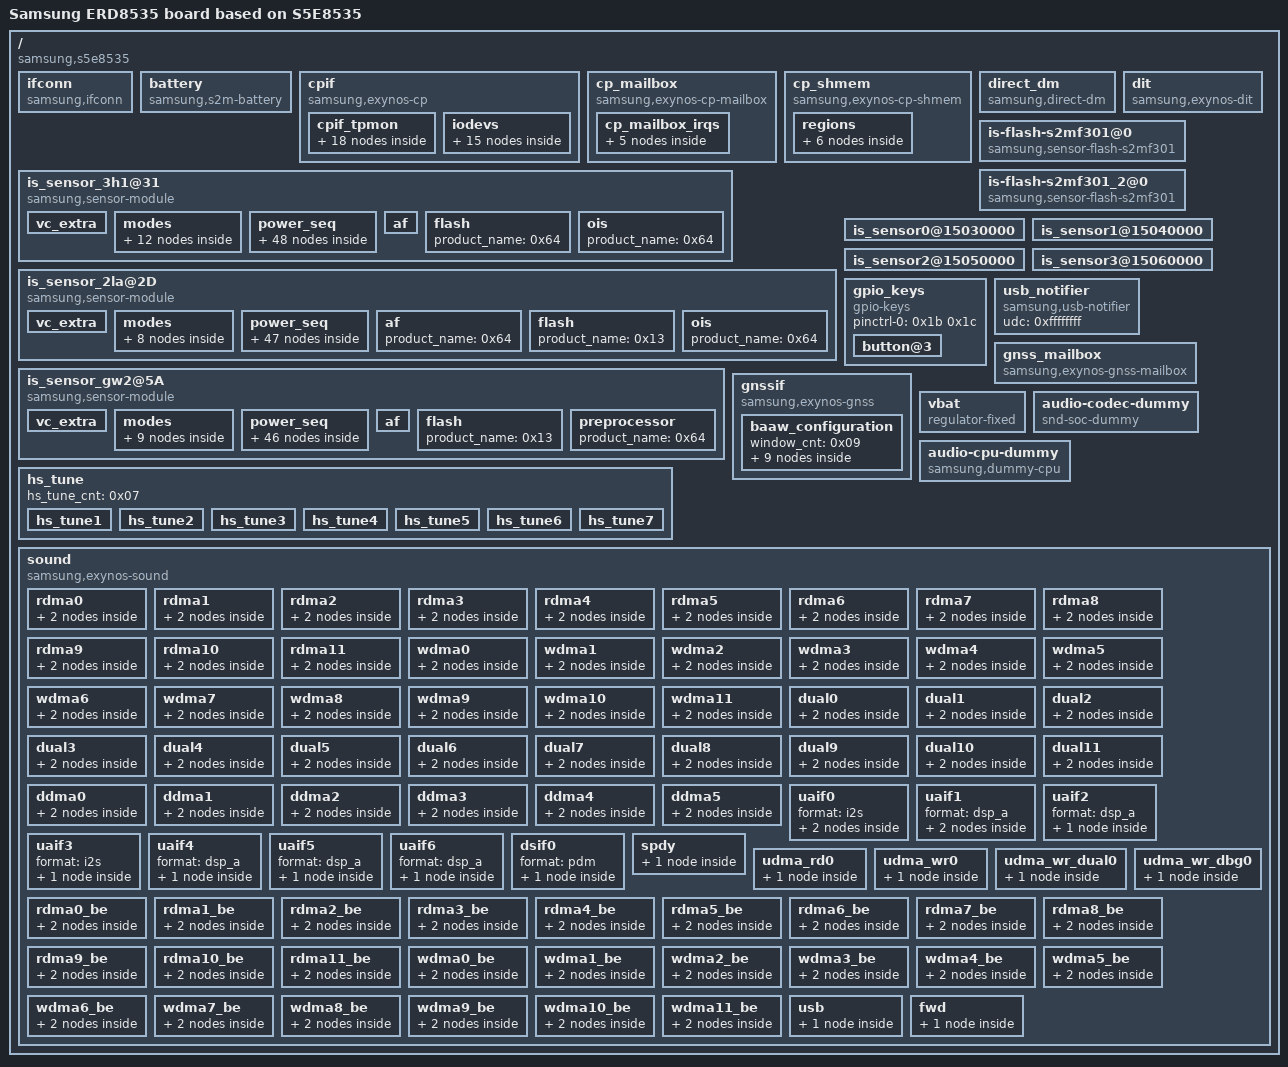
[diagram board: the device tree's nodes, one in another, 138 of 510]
/dts-v1/;

/ {
	compatible = "samsung,s5e8535\0samsung,ERD8535";
	board_id = <0x00>;
	board_rev = <0x00>;

	fragment@battery {
		target-path = "/";

		__overlay__ {

			ifconn {
				status = "okay";
				compatible = "samsung,ifconn";
				ifconn,usbpd = "s2mf301";
				ifconn,muic = "s2mf301-muic";
			};

			battery {
				status = "okay";
				compatible = "samsung,s2m-battery";
				pinctrl-names = "default";
				battery,vendor = "SDI SDI";
				battery,charger_name = "dc-manager";
				battery,direct_charger_name = "s2mc501-direct-charger";
				battery,switching_charger_name = "s2mf301-charger";
				battery,fuelgauge_name = "s2mf301-fuelgauge";
				battery,pmeter_name = "s2mf301-pmeter";
				battery,technology = <0x02>;
				battery,temp_high = <0x1f4>;
				battery,temp_high_recovery = <0x1c2>;
				battery,temp_low = <0x64>;
				battery,temp_low_recovery = <0x96>;
				battery,low_temp_limit = <0x64>;
				battery,chg_float_voltage = <0x10fe>;
				battery,full_check_count = <0x03>;
				battery,chg_full_vcell = <0x1108>;
				battery,chg_recharge_vcell = <0x10cc>;
				battery,max_rawsoc = <0x3e8>;
				battery,max_rawsoc_offset = <0x0a>;
				battery,default_input_current = <0x3e8>;
				battery,default_charging_current = <0x3e8>;
				battery,default_full_check_current = <0x12c>;
				battery,max_input_current = <0xbb8>;
				battery,max_charging_current = <0xbb8>;
				battery,pdo_max_input_vol = <0x32c8>;
				battery,pdo_max_chg_power = <0x61a8>;
				battery,input_current_limit = <0x1f4 0x1c2 0x1f4 0x7d0 0x1f4 0x4b0 0x4b0 0x3e8 0x3e8 0x5dc 0x3e8 0x1f4 0x1f4>;
				battery,fast_charging_current = <0x1f4 0x1c2 0x1f4 0x7d0 0x1f4 0x4b0 0x4b0 0x3e8 0x3e8 0xbb8 0x3e8 0x1f4 0x1f4>;
				battery,full_check_current = <0x12c 0x00 0x12c 0x12c 0x12c 0x12c 0x12c 0x12c 0x12c 0x12c 0x12c 0x12c 0x12c>;
				battery,input_current_limit_expand = <0xbb8 0x5dc 0x1f4 0x1c2>;
				battery,fast_charging_current_expand = <0xbb8 0xbb8 0x1f4 0x1c2>;
				battery,full_check_current_expand = <0x12c 0x12c 0x12c 0x00>;
				battery,thermal_limit_level = <0x258 0x2bc 0x320 0x384 0x3e8 0x44c 0x4b0>;
				battery,battery_table3 = <0x58 0x0b 0xd6 0x0a 0x54 0x0a 0xda 0x09 0x64 0x09 0xf3 0x08 0x8c 0x08 0x22 0x08 0xcd 0x07 0x7b 0x07 0x08 0x07 0xc6 0x06 0x97 0x06 0x71 0x06 0x54 0x06 0x39 0x06 0x0f 0x06 0xea 0x05 0xaf 0x05 0x85 0x05 0xfd 0x04 0xb2 0x01 0x69 0x08 0x00 0x08 0x97 0x07 0x2d 0x07 0xc4 0x06 0x5a 0x06 0xf1 0x05 0x87 0x05 0x1e 0x05 0xb5 0x04 0x4b 0x04 0xe2 0x03 0x78 0x03 0x0f 0x03 0xa6 0x02 0x3c 0x02 0xd3 0x01 0x69 0x01 0x00 0x01 0x96 0x00 0x2d 0x00 0xda 0x0f>;
				battery,battery_table4 = <0x21 0x21 0x21 0x21 0x21 0x21 0x21 0x21 0x21 0x20 0x20 0x21 0x21 0x21 0x21 0x22 0x22 0x22 0x22 0x24 0x26 0x7c>;
				battery,batcap = <0x8c 0x44 0x23 0x11>;
				battery,accum = <0x08 0x00>;
				battery,soc_arr_val = <0x2912 0x2710 0x250d 0x230a 0x2107 0x1f05 0x1d02 0x1aff 0x18fc 0x16fa 0x14f7 0x12f4 0x10f2 0xeef 0xcec 0xae9 0x8e7 0x6e4 0x4e1 0x2de 0xdc 0xffffff47>;
				battery,ocv_arr_val = <0xac93 0xaa18 0xa79e 0xa54b 0xa30c 0xa0e4 0x9eeb 0x9ce7 0x9b45 0x99b7 0x9787 0x9645 0x955d 0x94a6 0x9417 0x9392 0x92c6 0x920e 0x90f2 0x9024 0x8d8c 0x7d78>;
				battery,battery_param_ver = <0x03>;
			};
		};
	};

	fragment@modemif {
		target-path = "/";

		__overlay__ {
			#address-cells = <0x02>;
			#size-cells = <0x01>;

			cpif {
				compatible = "samsung,exynos-cp";
				status = "okay";
				pinctrl-names = "default";
				pinctrl-0 = <0x01>;
				interrupt-parent = <0xffffffff>;
				interrupts = <0x00 0x14f 0x04>;
				interrupt-names = "RESET_REQ";
				ap2cp_cfg_addr = <0x14020000>;
				mif,name = "s5408ap";
				mif,cp_num = <0x00>;
				mif,modem_type = <0x00>;
				mif,protocol = <0x01>;
				mif,ipc_version = <0x32>;
				mif,link_type = <0x00>;
				mif,link_name = "shmem";
				mif,link_attrs = <0x7c8>;
				mif,interrupt_types = <0x00>;
				mif,capability_check = <0x01>;
				mif,int_ap2cp_msg = <0x00>;
				mif,int_ap2cp_wakeup = <0x01>;
				mif,int_ap2cp_status = <0x02>;
				mif,int_ap2cp_active = <0x03>;
				mif,int_ap2cp_lcd_status = <0x04>;
				mif,int_ap2cp_llc_status = <0x05>;
				mif,int_ap2cp_clatinfo_send = <0x06>;
				mif,int_ap2cp_cp_reset_noti = <0x07>;
				mif,int_ap2cp_uart_noti = <0x0f>;
				mif,irq_cp2ap_msg = <0x00>;
				mif,irq_cp2ap_status = <0x02>;
				mif,irq_cp2ap_active = <0x03>;
				mif,irq_cp2ap_llc_status = <0x05>;
				mif,irq_cp2ap_clatinfo_ack = <0x06>;
				mif,irq_cp2ap_wakelock = <0x08>;
				mif,irq_cp2ap_ratmode = <0x09>;
				legacy_fmt_head_tail_offset = <0x10>;
				legacy_fmt_buffer_offset = <0x1000>;
				legacy_fmt_txq_size = <0x1000>;
				legacy_fmt_rxq_size = <0x1000>;
				legacy_raw_head_tail_offset = <0x20>;
				legacy_raw_buffer_offset = <0x3000>;
				legacy_raw_txq_size = <0x1fd000>;
				legacy_raw_rxq_size = <0x200000>;
				legacy_raw_qos_head_tail_offset = <0x30>;
				legacy_raw_qos_buffer_offset = <0x400000>;
				legacy_raw_qos_txq_size = <0x100000>;
				legacy_raw_qos_rxq_size = <0x100000>;
				legacy_raw_rx_buffer_cached = <0x00>;
				offset_cmsg_offset = <0x60>;
				offset_srinfo_offset = <0x64>;
				offset_clk_table_offset = <0x68>;
				offset_buff_desc_offset = <0x6c>;
				offset_capability_offset = <0x70>;
				cmsg_offset = <0xc0>;
				srinfo_offset = <0x300>;
				srinfo_size = <0x800>;
				clk_table_offset = <0x200>;
				buff_desc_offset = <0xc00>;
				capability_offset = <0xa0>;
				ap_capability_0 = <0x00>;
				ap_capability_1 = <0x00>;
				ap2cp_msg = <0x03 0x00>;
				cp2ap_msg = <0x03 0x04>;
				ap2cp_united_status = <0x03 0x08>;
				cp2ap_united_status = <0x03 0x0c>;
				ap2cp_llc_status = <0x03 0x10>;
				cp2ap_llc_status = <0x03 0x14>;
				ap2cp_clatinfo_xlat_v4_addr = <0x03 0x18>;
				ap2cp_clatinfo_xlat_addr_0 = <0x03 0x1c>;
				ap2cp_clatinfo_xlat_addr_1 = <0x03 0x20>;
				ap2cp_clatinfo_xlat_addr_2 = <0x03 0x24>;
				ap2cp_clatinfo_xlat_addr_3 = <0x03 0x28>;
				ap2cp_clatinfo_index = <0x03 0x2c>;
				ap2cp_kerneltime_sec = <0x03 0x38>;
				ap2cp_kerneltime_usec = <0x03 0x3c>;
				sbi_lcd_status_mask = <0x01>;
				sbi_lcd_status_pos = <0x1b>;
				sbi_crash_type_mask = <0x0f>;
				sbi_crash_type_pos = <0x17>;
				sbi_ext_backtrace_mask = <0x01>;
				sbi_ext_backtrace_pos = <0x11>;
				sbi_ext_backtrace_ext_mask = <0x01>;
				sbi_ext_backtrace_ext_pos = <0x12>;
				sbi_uart_noti_mask = <0x01>;
				sbi_uart_noti_pos = <0x10>;
				sbi_ds_det_mask = <0x03>;
				sbi_ds_det_pos = <0x0e>;
				sbi_sys_rev_mask = <0xff>;
				sbi_sys_rev_pos = <0x06>;
				sbi_pda_active_mask = <0x01>;
				sbi_pda_active_pos = <0x05>;
				sbi_tx_flowctl_mask = <0x01>;
				sbi_tx_flowctl_pos = <0x03>;
				sbi_ap_status_mask = <0x01>;
				sbi_ap_status_pos = <0x01>;
				sbi_cp_rat_mode_mask = <0x3f>;
				sbi_cp_rat_mode_pos = <0x1a>;
				sbi_cp_evs_mode_mask = <0x01>;
				sbi_cp_evs_mode_pos = <0x07>;
				sbi_cp2ap_wakelock_mask = <0x01>;
				sbi_cp2ap_wakelock_pos = <0x06>;
				sbi_lte_active_mask = <0x01>;
				sbi_lte_active_pos = <0x05>;
				sbi_cp_status_mask = <0x0f>;
				sbi_cp_status_pos = <0x01>;
				sbi_ap_llc_request_mask = <0x01>;
				sbi_ap_llc_request_pos = <0x0e>;
				sbi_ap_llc_target_mask = <0x01>;
				sbi_ap_llc_target_pos = <0x0d>;
				sbi_ap_llc_return_mask = <0x0f>;
				sbi_ap_llc_return_pos = <0x09>;
				sbi_ap_llc_alloc_mask = <0x01>;
				sbi_ap_llc_alloc_pos = <0x08>;
				sbi_ap_llc_way_mask = <0xff>;
				sbi_ap_llc_way_pos = <0x00>;
				sbi_cp_llc_request_mask = <0x01>;
				sbi_cp_llc_request_pos = <0x0e>;
				sbi_cp_llc_target_mask = <0x01>;
				sbi_cp_llc_target_pos = <0x0d>;
				sbi_cp_llc_return_mask = <0x0f>;
				sbi_cp_llc_return_pos = <0x09>;
				sbi_cp_llc_alloc_mask = <0x01>;
				sbi_cp_llc_alloc_pos = <0x08>;
				sbi_cp_llc_way_mask = <0xff>;
				sbi_cp_llc_way_pos = <0x00>;
				cp_btl_node_name = "ramdump_memshare";
				s2d_req_handle_support = <0x01>;
				s2d_req_pmu_reg = <0x3540>;
				s2d_req_reg_mask = <0x07>;
				pktproc_use_36bit_addr = <0x00>;
				pktproc_cp_base = <0x00 0x50800000>;
				pktproc_dl_support = <0x01>;
				pktproc_dl_version = <0x02>;
				pktproc_dl_info_rgn_offset = <0x00>;
				pktproc_dl_info_rgn_size = <0x1000>;
				pktproc_dl_desc_rgn_offset = <0x2000>;
				pktproc_dl_desc_rgn_size = <0xfe000>;
				pktproc_dl_buff_rgn_offset = <0x200000>;
				pktproc_dl_buff_rgn_size = <0x1200000>;
				pktproc_dl_info_rgn_cached = <0x00>;
				pktproc_dl_desc_rgn_cached = <0x00>;
				pktproc_dl_buff_rgn_cached = <0x00>;
				pktproc_dl_desc_mode = <0x01>;
				pktproc_dl_num_queue = <0x01>;
				pktproc_dl_use_exclusive_irq = <0x01>;
				pktproc_dl_exclusive_irq_idx = <0x01 0x02 0x03 0x04>;
				pktproc_dl_use_netrx_mng = <0x00>;
				pktproc_dl_use_hw_iocc = <0x00>;
				pktproc_dl_max_packet_size = <0x800>;
				pktproc_dl_use_dedicated_baaw = <0x00>;
				pktproc_ul_support = <0x01>;
				pktproc_ul_info_rgn_offset = <0x1000>;
				pktproc_ul_info_rgn_size = <0x1000>;
				pktproc_ul_desc_rgn_offset = <0x100000>;
				pktproc_ul_desc_rgn_size = <0x100000>;
				pktproc_ul_buff_rgn_offset = <0x1400000>;
				pktproc_ul_buff_rgn_size = <0x400000>;
				pktproc_ul_padding_required = <0x01>;
				pktproc_ul_num_queue = <0x02>;
				pktproc_ul_max_packet_size = <0x800>;
				pktproc_ul_info_rgn_cached = <0x00>;
				pktproc_ul_desc_rgn_cached = <0x00>;
				pktproc_ul_buff_rgn_cached = <0x00>;
				pktproc_ul_use_hw_iocc = <0x00>;
				devfreq_use_dfs_max_freq = <0x01>;
				devfreq_cal_id_mif = <0xb040000>;

				cpif_tpmon {
					trigger_msec_min = <0x1f4>;
					trigger_msec_max = <0x5dc>;
					monitor_interval_msec = <0x3e8>;
					monitor_hold_msec = <0xbb8>;
					monitor_stop_mbps = <0x0f>;
					boost_hold_msec = <0x1770>;

					tpmon_rps {
						boost_name = "RPS";
						target = <0x00>;
						extra_idx = <0x00>;
						level = <0x13 0x80>;

						boost0 {
							enable = <0x01>;
							measure = <0x00>;
							proto = <0x00>;
							boost_threshold = <0x12c>;
							unboost_threshold_mbps = <0x78>;
						};
					};

					tpmon_gro_flush_time {
						boost_name = "GRO";
						target = <0x01>;
						extra_idx = <0x00>;
						level = <0x1e8480 0x1e8480 0x1e8480>;

						boost0 {
							enable = <0x01>;
							measure = <0x00>;
							proto = <0x00>;
							boost_threshold = <0x64 0xc8>;
							unboost_threshold_mbps = <0x32 0x78>;
						};
					};

					tpmon_mif {
						boost_name = "MIF";
						target = <0x02>;
						extra_idx = <0x00>;
						level = <0x00 0xf78f0>;

						boost0 {
							enable = <0x01>;
							measure = <0x00>;
							proto = <0x01>;
							boost_threshold = <0x2bc>;
							unboost_threshold_mbps = <0x12c>;
						};
					};

					tpmon_cpu_cl0 {
						boost_name = "CL0";
						target = <0x09>;
						extra_idx = <0x00>;
						level = <0x00 0x101d00 0x119400>;

						boost0 {
							enable = <0x00>;
							measure = <0x00>;
							proto = <0x01>;
							boost_threshold = <0x64 0x12c>;
							unboost_threshold_mbps = <0x28 0x78>;
						};
					};

					tpmon_cpu_cl1 {
						boost_name = "CL1";
						target = <0x0a>;
						extra_idx = <0x06>;
						level = <0x00 0xbb800 0x119400 0x177000>;

						boost0 {
							enable = <0x00>;
							measure = <0x00>;
							proto = <0x01>;
							boost_threshold = <0x1f4 0x2bc 0x5dc>;
							unboost_threshold_mbps = <0xc8 0x12c 0x258>;
						};
					};

					tpmon_irq_dit {
						boost_name = "IRQ_DIT";
						target = <0x06>;
						extra_idx = <0x00>;
						level = <0x20 0x40>;

						boost0 {
							enable = <0x01>;
							measure = <0x00>;
							proto = <0x00>;
							boost_threshold = <0x7d0>;
							unboost_threshold_mbps = <0x320>;
						};

						boost1 {
							enable = <0x01>;
							measure = <0x02>;
							proto = <0x00>;
							boost_threshold = <0x1770>;
							unboost_threshold_mbps = <0x7d0>;
						};

						boost2 {
							enable = <0x01>;
							measure = <0x03>;
							proto = <0x00>;
							boost_threshold = <0x1b58>;
							unboost_threshold_mbps = <0x7d0>;
						};
					};

					tpmon_int_freq {
						boost_name = "INT";
						target = <0x07>;
						extra_idx = <0x00>;
						level = <0x00 0x61a80 0x82208>;

						boost0 {
							enable = <0x01>;
							measure = <0x00>;
							proto = <0x00>;
							boost_threshold = <0x6d6 0xbb8>;
							unboost_threshold_mbps = <0x320 0x4b0>;
						};
					};

					tpmon_bts_dit {
						boost_name = "BTS_DIT";
						target = <0x08>;
						extra_idx = <0x00>;
						level = <0x00 0x01>;

						boost0 {
							enable = <0x01>;
							measure = <0x03>;
							proto = <0x00>;
							boost_threshold = <0xfa0>;
							unboost_threshold_mbps = <0x12c>;
						};
					};
				};

				iodevs {

					io_device_0 {
						iod,name = "umts_ipc";
						iod,ch = <0xf5>;
						iod,format = <0x00>;
						iod,io_type = <0x01>;
						iod,link_type = <0x00>;
						iod,attrs = <0x2000>;
						iod,ch_count = <0x02>;
					};

					io_device_1 {
						iod,name = "umts_rfs0";
						iod,ch = <0x29>;
						iod,format = <0x01>;
						iod,io_type = <0x01>;
						iod,link_type = <0x00>;
						iod,attrs = <0x00>;
					};

					io_device_2 {
						iod,name = "umts_router";
						iod,ch = <0x15>;
						iod,format = <0x01>;
						iod,io_type = <0x01>;
						iod,link_type = <0x00>;
						iod,attrs = <0x00>;
					};

					io_device_3 {
						iod,name = "umts_dm0";
						iod,ch = <0x51>;
						iod,format = <0x01>;
						iod,io_type = <0x01>;
						iod,link_type = <0x00>;
						iod,attrs = <0x4000>;
					};

					io_device_4 {
						iod,name = "umts_loopback";
						iod,ch = <0x52>;
						iod,format = <0x01>;
						iod,io_type = <0x01>;
						iod,link_type = <0x00>;
						iod,attrs = <0x00>;
					};

					io_device_5 {
						iod,name = "rmnet";
						iod,ch = <0xb5>;
						iod,format = <0x01>;
						iod,io_type = <0x02>;
						iod,link_type = <0x00>;
						iod,attrs = <0x2000>;
						iod,ch_count = <0x1e>;
					};

					io_device_6 {
						iod,name = "umts_dummy";
						iod,ch = <0xd3>;
						iod,format = <0x01>;
						iod,io_type = <0x02>;
						iod,link_type = <0x00>;
						iod,attrs = <0x00>;
					};

					io_device_7 {
						iod,name = "multipdp";
						iod,ch = <0x00>;
						iod,format = <0x03>;
						iod,io_type = <0x03>;
						iod,link_type = <0x00>;
						iod,attrs = <0x00>;
					};

					io_device_8 {
						iod,name = "umts_boot0";
						iod,ch = <0xf1>;
						iod,format = <0x04>;
						iod,io_type = <0x00>;
						iod,link_type = <0x00>;
						iod,attrs = <0x4200>;
					};

					io_device_9 {
						iod,name = "umts_rcs0";
						iod,ch = <0x5b>;
						iod,format = <0x00>;
						iod,io_type = <0x01>;
						iod,link_type = <0x00>;
						iod,attrs = <0x00>;
					};

					io_device_10 {
						iod,name = "umts_rcs1";
						iod,ch = <0x5c>;
						iod,format = <0x01>;
						iod,io_type = <0x01>;
						iod,link_type = <0x00>;
						iod,attrs = <0x00>;
					};

					io_device_11 {
						iod,name = "umts_wfc0";
						iod,ch = <0x5d>;
						iod,format = <0x00>;
						iod,io_type = <0x01>;
						iod,link_type = <0x00>;
						iod,attrs = <0x00>;
					};

					io_device_12 {
						iod,name = "umts_wfc1";
						iod,ch = <0x5e>;
						iod,format = <0x01>;
						iod,io_type = <0x01>;
						iod,link_type = <0x00>;
						iod,attrs = <0x00>;
					};

					io_device_13 {
						iod,name = "umts_embms";
						iod,ch = <0x1e>;
						iod,format = <0x01>;
						iod,io_type = <0x02>;
						iod,link_type = <0x00>;
						iod,attrs = <0x2000>;
						iod,ch_count = <0x02>;
					};

					io_device_14 {
						iod,name = "umts_atc0";
						iod,ch = <0x17>;
						iod,format = <0x01>;
						iod,io_type = <0x01>;
						iod,link_type = <0x00>;
						iod,attrs = <0x00>;
					};
				};
			};

			cp_mailbox {
				compatible = "samsung,exynos-cp-mailbox";
				reg = <0x00 0x119b0000 0x200>;
				num_shared_reg = <0x0a>;
				shared_reg_offset = <0x100>;
				use_sw_reset_reg = <0x00>;
				interrupt-parent = <0xffffffff>;
				interrupts = <0x00 0x27 0x04 0x00 0x28 0x04 0x00 0x29 0x04 0x00 0x2a 0x04 0x00 0x2b 0x04>;

				cp_mailbox_irqs {

					cp_irq_0 {
						cp_irq,enable = <0x01>;
						cp_irq,idx = <0x00>;
						cp_irq,name = "cp_mbox_irq_0";
						cp_irq,sfr = <0x00 0x10 0x14 0x00>;
						cp_irq,affinity = <0x02>;
					};

					cp_irq_1 {
						cp_irq,enable = <0x01>;
						cp_irq,idx = <0x01>;
						cp_irq,name = "cp_mbox_irq_1";
						cp_irq,sfr = <0x28 0x00 0x14 0x00>;
						cp_irq,affinity = <0x03>;
					};

					cp_irq_2 {
						cp_irq,enable = <0x00>;
						cp_irq,idx = <0x02>;
						cp_irq,name = "cp_mbox_irq_2";
						cp_irq,sfr = <0x3c 0x00 0x14 0x00>;
						cp_irq,affinity = <0x02>;
					};

					cp_irq_3 {
						cp_irq,enable = <0x00>;
						cp_irq,idx = <0x03>;
						cp_irq,name = "cp_mbox_irq_3";
						cp_irq,sfr = <0x50 0x00 0x14 0x00>;
						cp_irq,affinity = <0x01>;
					};

					cp_irq_4 {
						cp_irq,enable = <0x01>;
						cp_irq,idx = <0x04>;
						cp_irq,name = "cp_mbox_irq_4";
						cp_irq,sfr = <0x64 0x00 0x14 0x00>;
						cp_irq,affinity = <0x02>;
					};
				};
			};

			cp_shmem {
				compatible = "samsung,exynos-cp-shmem";
				memory-region = <0xffffffff 0xffffffff>;
				cp_num = <0x00>;
				use_mem_map_on_cp = <0x01>;

				regions {

					cp {
						region,name = "CP";
						region,index = <0x00>;
						region,rmem = <0x00>;
						region,offset = <0x00>;
						region,size = <0xf400000>;
						region,cached = <0x00>;
					};

					vss {
						region,name = "VSS";
						region,index = <0x01>;
						region,rmem = <0x00>;
						region,offset = <0xf400000>;
						region,size = <0x800000>;
						region,cached = <0x00>;
					};

					ddm {
						region,name = "DDM";
						region,index = <0x0c>;
						region,rmem = <0x00>;
						region,offset = <0xfc00000>;
						region,size = <0x400000>;
					};

					ipc {
						region,name = "IPC";
						region,index = <0x03>;
						region,rmem = <0x01>;
						region,offset = <0x00>;
						region,size = <0x800000>;
						region,cached = <0x00>;
					};

					pktproc {
						region,name = "PKTPROC";
						region,index = <0x07>;
						region,rmem = <0x01>;
						region,offset = <0x800000>;
						region,size = <0x1800000>;
					};

					btl {
						region,name = "BTL";
						region,index = <0x05>;
						region,rmem = <0x01>;
						region,offset = <0x2000000>;
						region,size = <0x10000000>;
						region,cached = <0x00>;
					};
				};
			};

			direct_dm {
				compatible = "samsung,direct-dm";
				version = <0x02>;
				shm_rgn_index = <0x0c>;
				hw_iocc = <0x00>;
				info_desc_rgn_cached = <0x00>;
				buff_rgn_cached = <0x00>;
				info_rgn_offset = <0x00>;
				info_rgn_size = <0x100>;
				desc_rgn_offset = <0x100>;
				desc_rgn_size = <0x7f00>;
				buff_rgn_offset = <0x8000>;
				max_packet_size = <0x8000>;
				usb_req_num = <0x80>;
				irq_index = <0x04>;
				use_rx_task = <0x00>;
				use_rx_timer = <0x01>;
				rx_timer_period_msec = <0x3e8>;
			};
		};
	};

	fragment@0 {
		target = <0xffffffff>;

		__overlay__ {

			tray_detect {
				samsung,pins = "gpc0-0";
				samsung,pin-function = <0x0f>;
				samsung,pin-pud = <0x00>;
				phandle = <0x01>;
			};
		};
	};

	fragment@dit {
		target-path = "/";

		__overlay__ {
			#address-cells = <0x02>;
			#size-cells = <0x01>;

			dit {
				compatible = "samsung,exynos-dit";
				status = "okay";
				interrupt-parent = <0xffffffff>;
				interrupts = <0x00 0x151 0x04 0x00 0x153 0x04 0x00 0x155 0x04 0x00 0x15a 0x04>;
				interrupt-names = "DIT-RxDst00\0DIT-RxDst1\0DIT-RxDst2\0DIT-Tx";
				reg = <0x00 0x14580000 0x10000>;
				reg-names = "dit";
				dit_hw_capabilities = <0x00>;
				dit_use_tx = <0x01>;
				dit_use_rx = <0x01>;
				dit_use_clat = <0x00>;
				dit_use_recycling = <0x01>;
				dit_hal_support = <0x00>;
				dit_hal_enqueue_rx = <0x00>;
				dit_rx_extra_desc_ring_len = <0x800>;
				dit_irq_affinity = <0x04>;
			};
		};
	};

	fragment@camera {
		target-path = "/";

		__overlay__ {
			#address-cells = <0x02>;
			#size-cells = <0x01>;
			interrupt-parent = <0xffffffff>;

			is_sensor_3h1@31 {
				compatible = "samsung,sensor-module";
				active_width = <0xcd0>;
				active_height = <0x9a0>;
				margin_left = <0x00>;
				margin_right = <0x00>;
				margin_top = <0x00>;
				margin_bottom = <0x00>;
				max_framerate = <0x78>;
				bitwidth = <0x0a>;
				use_retention_mode = <0x01>;
				sensor_maker = "SLSI";
				sensor_name = "3H1";
				setfile_name = "setfile_3h1.bin";
				status = "okay";
				pinctrl-names = "pin0\0pin1\0pin2\0release";
				pinctrl-0;
				pinctrl-1 = <0xffffffff>;
				pinctrl-2 = <0xffffffff>;
				pinctrl-3;
				position = <0x01>;
				id = <0x01>;
				mclk_ch = <0x02>;
				sensor_i2c_ch = <0x04>;
				phandle = <0x0a>;

				vc_extra {
					stat0;
					stat1;
					stat2;
					stat3;
				};

				modes {

					mode0 {
						common = <0xcc0 0x990 0x1e 0x00 0x00 0x01 0x5c1 0x03 0x00 0x05 0x00>;
						vc0 = <0x00 0x2b 0xcc0 0x990 0x2b 0x00 0xcc0 0x990>;
						vc1 = <0x01 0x00 0x00 0x00 0x00 0x00 0x00 0x00>;
						vc2 = <0x00 0x12 0x00 0x00 0x12 0x00 0x00 0x00>;
						vc3 = <0x03 0x00 0x00 0x00 0x00 0x00 0x00 0x00>;
					};

					mode1 {
						common = <0x990 0x990 0x1e 0x00 0x01 0x01 0x5c1 0x03 0x00 0x05 0x00>;
						vc0 = <0x00 0x2b 0x990 0x990 0x2b 0x00 0x990 0x990>;
						vc1 = <0x01 0x00 0x00 0x00 0x00 0x00 0x00 0x00>;
						vc2 = <0x00 0x12 0x00 0x00 0x12 0x00 0x00 0x00>;
						vc3 = <0x03 0x00 0x00 0x00 0x00 0x00 0x00 0x00>;
					};

					mode2 {
						common = <0xcc0 0x72c 0x1e 0x00 0x02 0x01 0x5c1 0x03 0x00 0x05 0x00>;
						vc0 = <0x00 0x2b 0xcc0 0x72c 0x2b 0x00 0xcc0 0x72c>;
						vc1 = <0x01 0x00 0x00 0x00 0x00 0x00 0x00 0x00>;
						vc2 = <0x00 0x12 0x00 0x00 0x12 0x00 0x00 0x00>;
						vc3 = <0x03 0x00 0x00 0x00 0x00 0x00 0x00 0x00>;
					};

					mode3 {
						common = <0x660 0x396 0x3c 0x00 0x03 0x01 0x2cf 0x03 0x00 0x05 0x00>;
						vc0 = <0x00 0x2b 0x660 0x396 0x2b 0x00 0x660 0x396>;
						vc1 = <0x01 0x00 0x00 0x00 0x00 0x00 0x00 0x00>;
						vc2 = <0x00 0x12 0x00 0x00 0x12 0x00 0x00 0x00>;
						vc3 = <0x03 0x00 0x00 0x00 0x00 0x00 0x00 0x00>;
					};

					mode4 {
						common = <0x660 0x396 0x1e 0x00 0x04 0x01 0x2cf 0x03 0x00 0x05 0x00>;
						vc0 = <0x00 0x2b 0x660 0x396 0x2b 0x00 0x660 0x396>;
						vc1 = <0x01 0x00 0x00 0x00 0x00 0x00 0x00 0x00>;
						vc2 = <0x00 0x12 0x00 0x00 0x12 0x00 0x00 0x00>;
						vc3 = <0x03 0x00 0x00 0x00 0x00 0x00 0x00 0x00>;
					};

					mode5 {
						common = <0x660 0x4c8 0x1e 0x00 0x05 0x01 0x2cf 0x03 0x00 0x05 0x00>;
						vc0 = <0x00 0x2b 0x660 0x4c8 0x2b 0x00 0x660 0x4c8>;
						vc1 = <0x01 0x00 0x00 0x00 0x00 0x00 0x00 0x00>;
						vc2 = <0x00 0x12 0x00 0x00 0x12 0x00 0x00 0x00>;
						vc3 = <0x03 0x00 0x00 0x00 0x00 0x00 0x00 0x00>;
					};

					mode6 {
						common = <0x4c8 0x4c8 0x1e 0x00 0x06 0x01 0x6b7 0x03 0x00 0x05 0x00>;
						vc0 = <0x00 0x2b 0x4c8 0x4c8 0x2b 0x00 0x4c8 0x4c8>;
						vc1 = <0x01 0x00 0x00 0x00 0x00 0x00 0x00 0x00>;
						vc2 = <0x00 0x12 0x00 0x00 0x12 0x00 0x00 0x00>;
						vc3 = <0x03 0x00 0x00 0x00 0x00 0x00 0x00 0x00>;
					};

					mode7 {
						common = <0x320 0x258 0x78 0x00 0x07 0x01 0x16c 0x03 0x00 0x05 0x00>;
						vc0 = <0x00 0x2b 0x320 0x258 0x2b 0x00 0x320 0x258>;
						vc1 = <0x01 0x00 0x00 0x00 0x00 0x00 0x00 0x00>;
						vc2 = <0x00 0x12 0x00 0x00 0x12 0x00 0x00 0x00>;
						vc3 = <0x03 0x00 0x00 0x00 0x00 0x00 0x00 0x00>;
					};

					mode8 {
						common = <0x330 0x5b0 0x0f 0x00 0x08 0x01 0x5c1 0x03 0x00 0x05 0x00>;
						vc0 = <0x00 0x2b 0x330 0x5b0 0x2b 0x00 0x330 0x5b0>;
						vc1 = <0x01 0x00 0x00 0x00 0x00 0x00 0x00 0x00>;
						vc2 = <0x00 0x12 0x00 0x00 0x12 0x00 0x00 0x00>;
						vc3 = <0x03 0x00 0x00 0x00 0x00 0x00 0x00 0x00>;
					};

					mode9 {
						common = <0x198 0x2d8 0x66 0x00 0x09 0x01 0x2cf 0x03 0x00 0x05 0x00>;
						vc0 = <0x00 0x2b 0x198 0x2d8 0x2b 0x00 0x198 0x2d8>;
						vc1 = <0x01 0x00 0x00 0x00 0x00 0x00 0x00 0x00>;
						vc2 = <0x00 0x12 0x00 0x00 0x12 0x00 0x00 0x00>;
						vc3 = <0x03 0x00 0x00 0x00 0x00 0x00 0x00 0x00>;
					};

					mode10 {
						common = <0xcc0 0x638 0x1e 0x00 0x0a 0x01 0x5c1 0x03 0x00 0x05 0x00>;
						vc0 = <0x00 0x2b 0xcc0 0x638 0x2b 0x00 0xcc0 0x638>;
						vc1 = <0x01 0x00 0x00 0x00 0x00 0x00 0x00 0x00>;
						vc2 = <0x00 0x12 0x00 0x00 0x12 0x00 0x00 0x00>;
						vc3 = <0x03 0x00 0x00 0x00 0x00 0x00 0x00 0x00>;
					};

					mode11 {
						common = <0xcc0 0x990 0x1e 0x00 0x00 0x01 0x5c1 0x03 0x00 0x05 0x07>;
						vc0 = <0x00 0x2b 0xcc0 0x990 0x2b 0x00 0x660 0x4c8>;
						vc1 = <0x01 0x00 0x00 0x00 0x00 0x00 0x00 0x00>;
						vc2 = <0x00 0x12 0x00 0x00 0x12 0x00 0x00 0x00>;
						vc3 = <0x03 0x00 0x00 0x00 0x00 0x00 0x00 0x00>;
					};
				};

				power_seq {
					use = <0x01>;
					gpio_mclk = <0xffffffff 0x04 0x01>;

					scenario_normal_on {
						sensor_scenario = <0x00>;
						gpio_scenario = <0x00>;

						10 {
							pname = "sen_rst low";
							pin = <0x01 0x00 0x00>;
							gpio = <0xffffffff 0x00 0x01>;
						};

						20 {
							pname = "VDDIO_1.8V_CAMIO";
							pin = <0x05 0x01 0x01>;
							share = <0x01 0x00 0x01>;
						};

						30 {
							pname = "vdda_vtcam_2p8_en";
							pin = <0x01 0x01 0x00>;
							gpio = <0xffffffff 0x06 0x01>;
						};

						40 {
							pname = "vdd_vtcam_1p05_en";
							pin = <0x01 0x01 0x00>;
							gpio = <0xffffffff 0x02 0x01>;
						};

						50 {
							pname = "vdd_vtcam_af_2p8_en";
							pin = <0x01 0x01 0x3e8>;
							gpio = <0xffffffff 0x07 0x01>;
						};

						60 {
							pname = "on_i2c";
							pin = <0x06 0x01 0x00>;
						};

						70 {
							pname = "sen_rst high";
							pin = <0x01 0x01 0x00>;
							gpio = <0xffffffff 0x00 0x01>;
						};

						80 {
							pname = "pin";
							pin = <0x04 0x02 0x00>;
						};

						90 {
							pname = "MCLK";
							pin = <0x07 0x01 0x2328>;
						};
					};

					scenario_vision_on {
						sensor_scenario = <0x01>;
						gpio_scenario = <0x00>;

						10 {
							pname = "sen_rst low";
							pin = <0x01 0x00 0x00>;
							gpio = <0xffffffff 0x00 0x01>;
						};

						20 {
							pname = "VDDIO_1.8V_CAMIO";
							pin = <0x05 0x01 0x01>;
							share = <0x01 0x00 0x01>;
						};

						30 {
							pname = "vdda_vtcam_2p8_en";
							pin = <0x01 0x01 0x00>;
							gpio = <0xffffffff 0x06 0x01>;
						};

						40 {
							pname = "vdd_vtcam_1p05_en";
							pin = <0x01 0x01 0x00>;
							gpio = <0xffffffff 0x02 0x01>;
						};

						50 {
							pname = "vdd_vtcam_af_2p8_en";
							pin = <0x01 0x01 0x3e8>;
							gpio = <0xffffffff 0x07 0x01>;
						};

						60 {
							pname = "on_i2c";
							pin = <0x06 0x01 0x00>;
						};

						70 {
							pname = "sen_rst high";
							pin = <0x01 0x01 0x00>;
							gpio = <0xffffffff 0x00 0x01>;
						};

						80 {
							pname = "pin";
							pin = <0x04 0x02 0x00>;
						};

						90 {
							pname = "MCLK";
							pin = <0x07 0x01 0x2328>;
						};
					};

					scenario_normal_off {
						sensor_scenario = <0x00>;
						gpio_scenario = <0x01>;

						10 {
							pname = "MCLK";
							pin = <0x07 0x00 0x01>;
						};

						20 {
							pname = "pin";
							pin = <0x04 0x00 0x00>;
						};

						30 {
							pname = "pin";
							pin = <0x04 0x01 0x00>;
						};

						40 {
							pname = "pin";
							pin = <0x04 0x00 0x00>;
						};

						50 {
							pname = "sen_rst low";
							pin = <0x01 0x00 0x0a>;
							gpio = <0xffffffff 0x00 0x01>;
						};

						60 {
							pname = "off_i2c";
							pin = <0x06 0x00 0x00>;
						};

						70 {
							pname = "vdda_vtcam_2p8_en";
							pin = <0x01 0x00 0x00>;
							gpio = <0xffffffff 0x06 0x01>;
						};

						80 {
							pname = "vdd_vtcam_1p05_en";
							pin = <0x01 0x00 0x00>;
							gpio = <0xffffffff 0x02 0x01>;
						};

						90 {
							pname = "vdd_vtcam_af_2p8_en";
							pin = <0x01 0x00 0x00>;
							gpio = <0xffffffff 0x07 0x01>;
						};

						100 {
							pname = "VDDIO_1.8V_CAMIO";
							pin = <0x05 0x00 0x00>;
							share = <0x02 0x00 0x00>;
						};
					};

					scenario_vision_off {
						sensor_scenario = <0x01>;
						gpio_scenario = <0x01>;

						10 {
							pname = "MCLK";
							pin = <0x07 0x00 0x01>;
						};

						20 {
							pname = "pin";
							pin = <0x04 0x00 0x00>;
						};

						30 {
							pname = "pin";
							pin = <0x04 0x01 0x00>;
						};

						40 {
							pname = "pin";
							pin = <0x04 0x00 0x00>;
						};

						50 {
							pname = "sen_rst low";
							pin = <0x01 0x00 0x0a>;
							gpio = <0xffffffff 0x00 0x01>;
						};

						60 {
							pname = "off_i2c";
							pin = <0x06 0x00 0x00>;
						};

						70 {
							pname = "vdda_vtcam_2p8_en";
							pin = <0x01 0x00 0x00>;
							gpio = <0xffffffff 0x06 0x01>;
						};

						80 {
							pname = "vdd_vtcam_1p05_en";
							pin = <0x01 0x00 0x00>;
							gpio = <0xffffffff 0x02 0x01>;
						};

						90 {
							pname = "vdd_vtcam_af_2p8_en";
							pin = <0x01 0x00 0x00>;
							gpio = <0xffffffff 0x07 0x01>;
						};

						100 {
							pname = "VDDIO_1.8V_CAMIO";
							pin = <0x05 0x00 0x00>;
							share = <0x02 0x00 0x00>;
						};
					};

					scenario_read_rom_on {
						sensor_scenario = <0x04>;
						gpio_scenario = <0x00>;

						10 {
							pname;
							pin;
							gpio;
						};

						20 {
							pname;
							pin;
							gpio;
						};
					};

					scenario_read_rom_off {
						sensor_scenario = <0x04>;
						gpio_scenario = <0x01>;

						10 {
							pname;
							pin;
							gpio;
						};

						20 {
							pname;
							pin;
							gpio;
						};
					};
				};

				af {
					product_name = <0x12>;
					i2c_ch = <0x07>;
				};

				flash {
					product_name = <0x64>;
				};

				ois {
					product_name = <0x64>;
				};
			};

			is_sensor_2la@2D {
				compatible = "samsung,sensor-module";
				active_width = <0xfc0>;
				active_height = <0xbd0>;
				margin_left = <0x00>;
				margin_right = <0x00>;
				margin_top = <0x00>;
				margin_bottom = <0x00>;
				max_framerate = <0xf0>;
				bitwidth = <0x0a>;
				use_retention_mode = <0x00>;
				sensor_maker = "SLSI";
				sensor_name = "2LA";
				setfile_name = "setfile_2la.bin";
				status = "okay";
				pinctrl-names = "pin0\0pin1\0pin2\0release";
				pinctrl-0;
				pinctrl-1 = <0xffffffff>;
				pinctrl-2 = <0xffffffff>;
				pinctrl-3;
				position = <0x00>;
				id = <0x00>;
				mclk_ch = <0x01>;
				sensor_i2c_ch = <0x00>;
				phandle = <0x02>;

				vc_extra {
					stat0;
					stat1;
					stat2;
					stat3;
				};

				modes {

					mode0 {
						common = <0xfc0 0xbd0 0x1e 0x00 0x00 0x02 0x5dd 0x02 0x00 0x05>;
						vc0 = <0x00 0x2b 0xfc0 0xbd0 0x2b 0x00 0xfc0 0xbd0>;
						vc1 = <0x01 0x00 0x00 0x00 0x00 0x00 0x00 0x00>;
						vc2 = <0x02 0x00 0x00 0x00 0x00 0x00 0x00 0x00>;
						vc3 = <0x03 0x00 0x00 0x00 0x00 0x00 0x00 0x00>;
					};

					mode1 {
						common = <0xfc0 0x8dc 0x3c 0x00 0x01 0x02 0x5dd 0x02 0x00 0x05>;
						vc0 = <0x00 0x2b 0xfc0 0x8dc 0x2b 0x00 0xfc0 0x8dc>;
						vc1 = <0x01 0x00 0x00 0x00 0x00 0x00 0x00 0x00>;
						vc2 = <0x02 0x00 0x00 0x00 0x00 0x00 0x00 0x00>;
						vc3 = <0x03 0x00 0x00 0x00 0x00 0x00 0x00 0x00>;
					};

					mode2 {
						common = <0xfc0 0x8dc 0x1e 0x00 0x02 0x02 0x5dd 0x02 0x00 0x05>;
						vc0 = <0x00 0x2b 0xfc0 0x8dc 0x2b 0x00 0xfc0 0x8dc>;
						vc1 = <0x01 0x00 0x00 0x00 0x00 0x00 0x00 0x00>;
						vc2 = <0x02 0x00 0x00 0x00 0x00 0x00 0x00 0x00>;
						vc3 = <0x03 0x00 0x00 0x00 0x00 0x00 0x00 0x00>;
					};

					mode3 {
						common = <0x7e0 0x46e 0xf0 0x00 0x03 0x02 0x79e 0x02 0x00 0x05>;
						vc0 = <0x00 0x2b 0x7e0 0x46e 0x2b 0x00 0x7e0 0x46e>;
						vc1 = <0x01 0x00 0x00 0x00 0x00 0x00 0x00 0x00>;
						vc2 = <0x02 0x00 0x00 0x00 0x00 0x00 0x00 0x00>;
						vc3 = <0x03 0x00 0x00 0x00 0x00 0x00 0x00 0x00>;
					};

					mode4 {
						common = <0x7e0 0x46e 0x78 0x00 0x04 0x02 0x79e 0x02 0x00 0x05>;
						vc0 = <0x00 0x2b 0x7e0 0x46e 0x2b 0x00 0x7e0 0x46e>;
						vc1 = <0x01 0x00 0x00 0x00 0x00 0x00 0x00 0x00>;
						vc2 = <0x02 0x00 0x00 0x00 0x00 0x00 0x00 0x00>;
						vc3 = <0x03 0x00 0x00 0x00 0x00 0x00 0x00 0x00>;
					};

					mode5 {
						common = <0xfc0 0xbd0 0x3c 0x00 0x05 0x02 0x5dd 0x02 0x00 0x05>;
						vc0 = <0x00 0x2b 0xfc0 0xbd0 0x2b 0x00 0xfc0 0xbd0>;
						vc1 = <0x01 0x00 0x00 0x00 0x00 0x00 0x00 0x00>;
						vc2 = <0x02 0x00 0x00 0x00 0x00 0x00 0x00 0x00>;
						vc3 = <0x03 0x00 0x00 0x00 0x00 0x00 0x00 0x00>;
					};

					mode6 {
						common = <0xfc0 0xbd0 0x1e 0x00 0x00 0x02 0x5dd 0x02 0x00 0x05 0x02>;
						vc0 = <0x00 0x2b 0xfc0 0xbd0 0x2b 0x00 0xfc0 0xbd0>;
						vc1 = <0x01 0x00 0x00 0x00 0x00 0x00 0x00 0x00>;
						vc2 = <0x02 0x00 0x00 0x00 0x00 0x00 0x00 0x00>;
						vc3 = <0x03 0x00 0x00 0x00 0x00 0x00 0x00 0x00>;
					};

					mode7 {
						common = <0xfc0 0x8dc 0x1e 0x00 0x02 0x02 0x5dd 0x02 0x00 0x05 0x02>;
						vc0 = <0x00 0x2b 0xfc0 0x8dc 0x2b 0x00 0xfc0 0x8dc>;
						vc1 = <0x01 0x00 0x00 0x00 0x00 0x00 0x00 0x00>;
						vc2 = <0x02 0x00 0x00 0x00 0x00 0x00 0x00 0x00>;
						vc3 = <0x03 0x00 0x00 0x00 0x00 0x00 0x00 0x00>;
					};
				};

				power_seq {
					use = <0x01>;
					gpio_mclk = <0xffffffff 0x03 0x01>;

					scenario_normal_on {
						sensor_scenario = <0x00>;
						gpio_scenario = <0x00>;

						10 {
							pname = "sen_rst low";
							pin = <0x01 0x00 0x00>;
							gpio = <0xffffffff 0x00 0x01>;
						};

						20 {
							pname = "VDDA_2.8V_UWCAM";
							pin = <0x05 0x01 0x00>;
						};

						30 {
							pname = "VDDD_1.05V_UWCAM";
							pin = <0x05 0x01 0x00>;
						};

						40 {
							pname = "VDDIO_1.8V_CAMIO";
							pin = <0x05 0x01 0x00>;
							share = <0x01 0x00 0x01>;
						};

						50 {
							pname = "on_i2c";
							pin = <0x06 0x01 0x0a>;
						};

						60 {
							pname = "sen_rst high";
							pin = <0x01 0x01 0x12c>;
							gpio = <0xffffffff 0x00 0x01>;
						};

						70 {
							pname = "pin";
							pin = <0x04 0x02 0x00>;
						};

						80 {
							pname = "MCLK";
							pin = <0x07 0x01 0x7d0>;
						};
					};

					scenario_normal_off {
						sensor_scenario = <0x00>;
						gpio_scenario = <0x01>;

						10 {
							pname = "sen_rst low";
							pin = <0x01 0x00 0x00>;
							gpio = <0xffffffff 0x00 0x01>;
						};

						20 {
							pname = "off_i2c";
							pin = <0x06 0x00 0x00>;
						};

						30 {
							pname = "VDDIO_1.8V_CAMIO";
							pin = <0x05 0x00 0x00>;
							share = <0x02 0x00 0x00>;
						};

						40 {
							pname = "VDDD_1.05V_UWCAM";
							pin = <0x05 0x00 0x00>;
						};

						50 {
							pname = "VDDA_2.8V_UWCAM";
							pin = <0x05 0x00 0x00>;
						};

						60 {
							pname = "MCLK";
							pin = <0x07 0x00 0x00>;
						};

						70 {
							pname = "pin";
							pin = <0x01 0x00 0x00>;
						};
					};

					scenario_vision_on {
						sensor_scenario = <0x01>;
						gpio_scenario = <0x00>;

						10 {
							pname = "sen_rst low";
							pin = <0x01 0x00 0x00>;
							gpio = <0xffffffff 0x00 0x01>;
						};

						20 {
							pname = "VDDA_2.8V_UWCAM";
							pin = <0x05 0x01 0x00>;
						};

						30 {
							pname = "VDDD_1.05V_UWCAM";
							pin = <0x05 0x01 0x00>;
						};

						40 {
							pname = "VDDIO_1.8V_CAMIO";
							pin = <0x05 0x01 0x00>;
							share = <0x01 0x00 0x01>;
						};

						50 {
							pname = "on_i2c";
							pin = <0x06 0x01 0x0a>;
						};

						60 {
							pname = "sen_rst high";
							pin = <0x01 0x01 0x12c>;
							gpio = <0xffffffff 0x00 0x01>;
						};

						70 {
							pname = "pin";
							pin = <0x04 0x02 0x00>;
						};

						80 {
							pname = "MCLK";
							pin = <0x07 0x01 0x7d0>;
						};
					};

					scenario_vision_off {
						sensor_scenario = <0x01>;
						gpio_scenario = <0x01>;

						10 {
							pname = "sen_rst low";
							pin = <0x01 0x00 0x00>;
							gpio = <0xffffffff 0x00 0x01>;
						};

						20 {
							pname = "off_i2c";
							pin = <0x06 0x00 0x00>;
						};

						30 {
							pname = "VDDIO_1.8V_CAMIO";
							pin = <0x05 0x00 0x00>;
							share = <0x02 0x00 0x00>;
						};

						40 {
							pname = "VDDD_1.05V_UWCAM";
							pin = <0x05 0x00 0x00>;
						};

						50 {
							pname = "VDDA_2.8V_UWCAM";
							pin = <0x05 0x00 0x00>;
						};

						60 {
							pname = "MCLK";
							pin = <0x07 0x00 0x00>;
						};

						70 {
							pname = "pin";
							pin = <0x01 0x00 0x00>;
						};
					};

					scenario_hw_init_normal_on {
						sensor_scenario = <0x07>;
						gpio_scenario = <0x00>;

						10 {
							pname;
							pin;
							gpio;
						};

						20 {
							pname;
							pin;
							gpio;
						};

						30 {
							pname;
							pin;
							gpio;
						};

						40 {
							pname;
							pin;
							gpio;
						};

						50 {
							pname;
							pin;
							gpio;
						};

						60 {
							pname;
							pin;
							gpio;
						};

						70 {
							pname;
							pin;
							gpio;
						};

						80 {
							pname;
							pin;
							gpio;
						};

						90 {
							pname;
							pin;
							gpio;
						};

						100 {
							pname;
							pin;
							gpio;
						};

						110 {
							pname;
							pin;
							gpio;
						};

						120 {
							pname;
							pin;
							gpio;
						};
					};
				};

				af {
					product_name = <0x64>;
				};

				flash {
					product_name = <0x13>;
				};

				ois {
					product_name = <0x64>;
				};
			};

			is_sensor_gw2@5A {
				compatible = "samsung,sensor-module";
				active_width = <0x2420>;
				active_height = <0x1b18>;
				margin_left = <0x00>;
				margin_right = <0x00>;
				margin_top = <0x00>;
				margin_bottom = <0x00>;
				max_framerate = <0xf0>;
				bitwidth = <0x0a>;
				use_retention_mode = <0x00>;
				sensor_maker = "SLSI";
				sensor_name = "GW2";
				setfile_name = "setfile_gw2.bin";
				status = "okay";
				pinctrl-names = "pin0\0pin1\0pin2\0release";
				pinctrl-0;
				pinctrl-1 = <0xffffffff>;
				pinctrl-2 = <0xffffffff>;
				pinctrl-3;
				position = <0x02>;
				id = <0x02>;
				mclk_ch = <0x00>;
				sensor_i2c_ch = <0x01>;
				phandle = <0x03>;

				vc_extra {
					stat0;
					stat1 = <0x3e8 0x195 0x488 0x6c8 0x02>;
					stat2;
					stat3 = <0x3e9 0x195 0x488 0x6c8 0x02>;
					stat_vc = <0x02>;
				};

				modes {

					mode0 {
						common = <0x2420 0x1b18 0x0f 0x00 0x00 0x02 0x6ab 0x02 0x00 0x05>;
						vc0 = <0x00 0x2b 0x2420 0x1b18 0x2b 0x00 0x2420 0x1b18>;
						vc1 = <0x02 0x00 0x00 0x00 0x00 0x00 0x00 0x00>;
						vc2 = <0x01 0x22b 0x480 0x6b8 0x2b 0x00 0x00 0x00>;
						vc3 = <0x03 0x00 0x00 0x00 0x00 0x00 0x00 0x00>;

						option {
							special_mode = <0x02>;
						};
					};

					mode1 {
						common = <0x1300 0xe40 0x1e 0x00 0x01 0x02 0x5ca 0x02 0x00 0x04>;
						vc0 = <0x00 0x2b 0x1300 0xe40 0x2b 0x00 0x1300 0xe40>;
						vc1 = <0x02 0x00 0x00 0x00 0x00 0x00 0x00 0x00>;
						vc2 = <0x01 0x22b 0x260 0x388 0x2b 0x01 0x260 0x388>;
						vc3 = <0x03 0x00 0x00 0x00 0x00 0x00 0x00 0x00>;
					};

					mode2 {
						common = <0x1300 0xab0 0x1e 0x00 0x02 0x02 0x5ca 0x02 0x00 0x04>;
						vc0 = <0x00 0x2b 0x1300 0xab0 0x2b 0x00 0x1300 0xab0>;
						vc1 = <0x02 0x00 0x00 0x00 0x00 0x00 0x00 0x00>;
						vc2 = <0x01 0x22b 0x260 0x2a8 0x2b 0x01 0x260 0x2a8>;
						vc3 = <0x03 0x00 0x00 0x00 0x00 0x00 0x00 0x00>;
					};

					mode3 {
						common = <0x1210 0xd8c 0x1e 0x00 0x03 0x02 0x5ca 0x02 0x00 0x04>;
						vc0 = <0x00 0x2b 0x1210 0xd8c 0x2b 0x00 0x1210 0xd8c>;
						vc1 = <0x02 0x00 0x00 0x00 0x00 0x00 0x00 0x00>;
						vc2 = <0x01 0x22b 0x480 0x6b0 0x2b 0x01 0x480 0x6b0>;
						vc3 = <0x03 0x00 0x00 0x00 0x00 0x00 0x00 0x00>;
					};

					mode4 {
						common = <0x1210 0xa2c 0x1e 0x00 0x04 0x02 0x5ca 0x02 0x00 0x04>;
						vc0 = <0x00 0x2b 0x1210 0xa2c 0x2b 0x00 0x1210 0xa2c>;
						vc1 = <0x02 0x00 0x00 0x00 0x00 0x00 0x00 0x00>;
						vc2 = <0x01 0x22b 0x480 0x500 0x2b 0x01 0x480 0x500>;
						vc3 = <0x03 0x00 0x00 0x00 0x00 0x00 0x00 0x00>;
					};

					mode5 {
						common = <0x1210 0xa2c 0x3c 0x00 0x05 0x02 0x606 0x02 0x00 0x04>;
						vc0 = <0x00 0x2b 0x1210 0xa2c 0x2b 0x00 0x1210 0xa2c>;
						vc1 = <0x02 0x00 0x00 0x00 0x00 0x00 0x00 0x00>;
						vc2 = <0x01 0x22b 0x480 0x500 0x2b 0x01 0x480 0x500>;
						vc3 = <0x03 0x00 0x00 0x00 0x00 0x00 0x00 0x00>;
					};

					mode6 {
						common = <0x780 0x438 0x78 0x00 0x06 0x02 0x5ca 0x02 0x00 0x05>;
						vc0 = <0x00 0x2b 0x780 0x438 0x2b 0x00 0x780 0x438>;
						vc1 = <0x01 0x00 0x00 0x00 0x00 0x00 0x00 0x00>;
						vc2 = <0x02 0x00 0x00 0x00 0x00 0x00 0x00 0x00>;
						vc3 = <0x03 0x00 0x00 0x00 0x00 0x00 0x00 0x00>;
					};

					mode7 {
						common = <0x780 0x438 0xf0 0x00 0x07 0x02 0x5ca 0x02 0x00 0x05>;
						vc0 = <0x00 0x2b 0x780 0x438 0x2b 0x00 0x780 0x438>;
						vc1 = <0x01 0x00 0x00 0x00 0x00 0x00 0x00 0x00>;
						vc2 = <0x02 0x00 0x00 0x00 0x00 0x00 0x00 0x00>;
						vc3 = <0x03 0x00 0x00 0x00 0x00 0x00 0x00 0x00>;
					};
				};

				power_seq {
					use = <0x01>;
					gpio_mclk = <0xffffffff 0x02 0x01>;

					scenario_normal_on {
						sensor_scenario = <0x00>;
						gpio_scenario = <0x00>;

						10 {
							pname = "sen_rst low";
							pin = <0x01 0x00 0x00>;
							gpio = <0xffffffff 0x01 0x01>;
						};

						20 {
							pname = "VDDD_1.05V_TELECAM";
							pin = <0x05 0x01 0x01>;
						};

						30 {
							pname = "VDDAF_2.8V_TELECAM";
							pin = <0x05 0x01 0x01>;
						};

						40 {
							pname = "VDDA_2.8V_TELECAM";
							pin = <0x05 0x01 0x01>;
						};

						50 {
							pname = "VDDIO_1.8V_CAMIO";
							pin = <0x05 0x01 0x01>;
							share = <0x01 0x00 0x01>;
						};

						60 {
							pname = "VDDOIS_2.8V_TELECAM";
							pin = <0x05 0x01 0x3e8>;
						};

						70 {
							pname = "on_i2c";
							pin = <0x06 0x01 0x00>;
						};

						80 {
							pname = "sen_rst high";
							pin = <0x01 0x01 0x00>;
							gpio = <0xffffffff 0x01 0x01>;
						};

						90 {
							pname = "pin";
							pin = <0x04 0x02 0x00>;
						};

						100 {
							pname = "MCLK";
							pin = <0x07 0x01 0x7d0>;
							gpio = <0xffffffff 0x00 0x01>;
						};
					};

					scenario_normal_off {
						sensor_scenario = <0x00>;
						gpio_scenario = <0x01>;

						10 {
							pname = "sen_rst low";
							pin = <0x01 0x00 0x0a>;
							gpio = <0xffffffff 0x01 0x01>;
						};

						20 {
							pname = "off_i2c";
							pin = <0x06 0x00 0x00>;
						};

						30 {
							pname = "VDDD_1.05V_TELECAM";
							pin = <0x05 0x00 0x00>;
						};

						40 {
							pname = "VDDAF_2.8V_TELECAM";
							pin = <0x05 0x00 0x00>;
						};

						50 {
							pname = "VDDA_2.8V_TELECAM";
							pin = <0x05 0x00 0x00>;
						};

						60 {
							pname = "VDDIO_1.8V_CAMIO";
							pin = <0x05 0x00 0x00>;
							share = <0x02 0x00 0x00>;
						};

						70 {
							pname = "VDDOIS_2.8V_TELECAM";
							pin = <0x05 0x00 0x3e8>;
						};

						80 {
							pname = "MCLK";
							pin = <0x07 0x00 0x00>;
						};

						90 {
							pname = "pin";
							pin = <0x04 0x00 0x00>;
						};

						100 {
							pname = "pin";
							pin = <0x04 0x01 0x00>;
						};

						110 {
							pname = "pin";
							pin = <0x04 0x00 0x00>;
						};
					};

					scenario_vision_on {
						sensor_scenario = <0x01>;
						gpio_scenario = <0x00>;

						10 {
							pname = "sen_rst low";
							pin = <0x01 0x00 0x00>;
							gpio = <0xffffffff 0x01 0x01>;
						};

						20 {
							pname = "VDDD_1.05V_TELECAM";
							pin = <0x05 0x01 0x01>;
						};

						30 {
							pname = "VDDAF_2.8V_TELECAM";
							pin = <0x05 0x01 0x01>;
						};

						40 {
							pname = "VDDA_2.8V_TELECAM";
							pin = <0x05 0x01 0x01>;
						};

						50 {
							pname = "VDDIO_1.8V_CAMIO";
							pin = <0x05 0x01 0x01>;
							share = <0x01 0x00 0x01>;
						};

						60 {
							pname = "VDDOIS_2.8V_TELECAM";
							pin = <0x05 0x01 0x3e8>;
						};

						70 {
							pname = "on_i2c";
							pin = <0x06 0x01 0x00>;
						};

						80 {
							pname = "sen_rst high";
							pin = <0x01 0x01 0x00>;
							gpio = <0xffffffff 0x01 0x01>;
						};

						90 {
							pname = "pin";
							pin = <0x04 0x02 0x00>;
						};

						100 {
							pname = "MCLK";
							pin = <0x07 0x01 0x7d0>;
							gpio = <0xffffffff 0x00 0x01>;
						};
					};

					scenario_vision_off {
						sensor_scenario = <0x01>;
						gpio_scenario = <0x01>;

						10 {
							pname = "sen_rst low";
							pin = <0x01 0x00 0x0a>;
							gpio = <0xffffffff 0x01 0x01>;
						};

						20 {
							pname = "off_i2c";
							pin = <0x06 0x00 0x00>;
						};

						30 {
							pname = "VDDD_1.05V_TELECAM";
							pin = <0x05 0x00 0x00>;
						};

						40 {
							pname = "VDDAF_2.8V_TELECAM";
							pin = <0x05 0x00 0x00>;
						};

						50 {
							pname = "VDDA_2.8V_TELECAM";
							pin = <0x05 0x00 0x00>;
						};

						60 {
							pname = "VDDIO_1.8V_CAMIO";
							pin = <0x05 0x00 0x00>;
							share = <0x02 0x00 0x00>;
						};

						70 {
							pname = "VDDOIS_2.8V_TELECAM";
							pin = <0x05 0x00 0x3e8>;
						};

						80 {
							pname = "MCLK";
							pin = <0x07 0x00 0x00>;
						};

						90 {
							pname = "pin";
							pin = <0x04 0x00 0x00>;
						};

						100 {
							pname = "pin";
							pin = <0x04 0x01 0x00>;
						};

						110 {
							pname = "pin";
							pin = <0x04 0x00 0x00>;
						};
					};
				};

				af {
					product_name = <0x12>;
					i2c_ch = <0x05>;
				};

				flash {
					product_name = <0x13>;
				};

				preprocessor {
					product_name = <0x64>;
				};
			};

			is-flash-s2mf301@0 {
				compatible = "samsung,sensor-flash-s2mf301";
				sensor-module = <0x02>;
				id = <0x00>;
				led_ch = <0x01>;
				status = "okay";
				phandle = <0x3a>;
			};

			is-flash-s2mf301_2@0 {
				compatible = "samsung,sensor-flash-s2mf301";
				sensor-module = <0x03>;
				id = <0x02>;
				led_ch = <0x01>;
				status = "okay";
				phandle = <0x3b>;
			};

			is_sensor0@15030000 {
				#address-cells = <0x01>;
				#size-cells = <0x01>;
				scenario = <0x00>;
				id = <0x00>;
				csi_ch = <0x00>;
				status = "okay";
				use_cphy = <0x01>;
				interrupts = <0x00 0xc0 0x04>;
				interrupt-names = "csi";
				phys = <0xffffffff 0x00>;
				phy_setfile = <0xffffffff>;
				phandle = <0x3c>;
			};

			is_sensor1@15040000 {
				#address-cells = <0x01>;
				#size-cells = <0x01>;
				reg = <0x00 0x15050000 0x1000 0x00 0x150f0000 0x10000>;
				scenario = <0x00>;
				id = <0x01>;
				csi_ch = <0x02>;
				status = "okay";
				use_cphy = <0x00>;
				interrupts = <0x00 0xc2 0x04>;
				interrupt-names = "csi";
				phys = <0xffffffff 0x00>;
				phy_setfile = <0xffffffff>;
				phandle = <0x3d>;
			};

			is_sensor2@15050000 {
				#address-cells = <0x01>;
				#size-cells = <0x01>;
				reg = <0x00 0x15040000 0x1000 0x00 0x150f0000 0x10000>;
				scenario = <0x00>;
				id = <0x02>;
				csi_ch = <0x01>;
				status = "okay";
				use_cphy = <0x01>;
				interrupts = <0x00 0xc1 0x04>;
				interrupt-names = "csi";
				phys = <0xffffffff 0x00>;
				phy_setfile = <0xffffffff>;
				phandle = <0x3e>;
			};

			is_sensor3@15060000 {
				#address-cells = <0x01>;
				#size-cells = <0x01>;
				reg = <0x00 0x15060000 0x1000 0x00 0x150f0000 0x10000>;
				scenario = <0x00>;
				id = <0x03>;
				csi_ch = <0x03>;
				status = "okay";
				use_cphy = <0x00>;
				interrupts = <0x00 0xc3 0x04>;
				phys = <0xffffffff 0x00>;
				phy_setfile = <0xffffffff>;
				phandle = <0x3f>;
			};
		};
	};

	fragment@1 {
		target = <0xffffffff>;

		__overlay__ {

			hsi2c23-bus {
				samsung,pins = "gpm6-0\0gpm7-0";
				samsung,pin-function = <0x03>;
				samsung,pin-pud = <0x03>;
				samsung,pin-drv = <0x00>;
				phandle = <0x05>;
			};

			hsi2c23-bus-in {
				samsung,pins = "gpm6-0\0gpm7-0";
				samsung,pin-function = <0x00>;
				samsung,pin-pud = <0x03>;
				samsung,pin-drv = <0x00>;
				phandle = <0x04>;
			};

			hsi2c29-bus {
				samsung,pins = "gpm19-0\0gpm20-0";
				samsung,pin-function = <0x03>;
				samsung,pin-pud = <0x03>;
				samsung,pin-drv = <0x00>;
				phandle = <0x07>;
			};

			hsi2c29-bus-in {
				samsung,pins = "gpm19-0\0gpm20-0";
				samsung,pin-function = <0x00>;
				samsung,pin-pud = <0x03>;
				samsung,pin-drv = <0x00>;
				phandle = <0x06>;
			};

			hsi2c28-bus {
				samsung,pins = "gpm17-0\0gpm18-0";
				samsung,pin-function = <0x02>;
				samsung,pin-pud = <0x03>;
				samsung,pin-drv = <0x00>;
				phandle = <0x0e>;
			};

			hsi2c28-bus-in {
				samsung,pins = "gpm17-0\0gpm18-0";
				samsung,pin-function = <0x00>;
				samsung,pin-pud = <0x03>;
				samsung,pin-drv = <0x00>;
				phandle = <0x0d>;
			};

			hsi2c25-bus {
				samsung,pins = "gpm10-0\0gpm11-0";
				samsung,pin-function = <0x03>;
				samsung,pin-pud = <0x03>;
				samsung,pin-drv = <0x00>;
				phandle = <0x0c>;
			};

			hsi2c25-bus-n {
				samsung,pins = "gpm10-0\0gpm11-0";
				samsung,pin-function = <0x00>;
				samsung,pin-pud = <0x03>;
				samsung,pin-drv = <0x00>;
				phandle = <0x0b>;
			};

			hsi2c20-bus {
				samsung,pins = "gpm0-0\0gpm1-0";
				samsung,pin-function = <0x02>;
				samsung,pin-pud = <0x03>;
				samsung,pin-drv = <0x00>;
				phandle = <0x09>;
			};

			hsi2c20-bus-in {
				samsung,pins = "gpm0-0\0gpm1-0";
				samsung,pin-function = <0x00>;
				samsung,pin-pud = <0x03>;
				samsung,pin-drv = <0x00>;
				phandle = <0x08>;
			};

			hsi2c21-bus {
				samsung,pins = "gpm2-0\0gpm3-0";
				samsung,pin-function = <0x03>;
				samsung,pin-pud = <0x03>;
				samsung,pin-drv = <0x00>;
				phandle = <0x10>;
			};

			hsi2c21-bus-in {
				samsung,pins = "gpm2-0\0gpm3-0";
				samsung,pin-function = <0x00>;
				samsung,pin-pud = <0x03>;
				samsung,pin-drv = <0x00>;
				phandle = <0x0f>;
			};
		};
	};

	fragment@2 {
		target = <0xffffffff>;

		__overlay__ {
			#address-cells = <0x01>;
			#size-cells = <0x00>;
			gpios = <0xffffffff 0x00 0x00 0xffffffff 0x00 0x00>;
			status = "okay";
			clock-frequency = <0xf4240>;
			samsung,reset-before-trans;
			samsung,fast-plus-mode;
			pinctrl-names = "default\0on_i2c\0off_i2c";
			pinctrl-0 = <0x04>;
			pinctrl-1 = <0x05>;
			pinctrl-2 = <0x04>;

			is-2la@2D {
				compatible = "samsung,exynos-is-cis-2la";
				sensor-module = <0x02>;
				reg = <0x2d>;
				id = <0x00>;
				setfile = "setA";
				status = "okay";
				rev_reg = <0x02 0x02 0xa202>;
			};
		};
	};

	fragment@3 {
		target = <0xffffffff>;

		__overlay__ {
			#address-cells = <0x01>;
			#size-cells = <0x00>;
			gpios = <0xffffffff 0x00 0x00 0xffffffff 0x00 0x00>;
			status = "okay";
			clock-frequency = <0xf4240>;
			samsung,reset-before-trans;
			samsung,fast-plus-mode;
			pinctrl-names = "default\0on_i2c\0off_i2c";
			pinctrl-0 = <0x06>;
			pinctrl-1 = <0x07>;
			pinctrl-2 = <0x06>;

			is-gw2@5A {
				compatible = "samsung,exynos-is-cis-gw2";
				sensor-module = <0x03>;
				reg = <0x2d>;
				id = <0x02>;
				setfile = "setC";
				status = "okay";
				rev_reg = <0x02 0x02 0xa300>;
			};
		};
	};

	fragment@4 {
		target = <0xffffffff>;

		__overlay__ {
			#address-cells = <0x01>;
			#size-cells = <0x00>;
			gpios = <0xffffffff 0x00 0x00 0xffffffff 0x00 0x00>;
			status = "okay";
			clock-frequency = <0xf4240>;
			samsung,reset-before-trans;
			samsung,fast-plus-mode;
			pinctrl-names = "default\0on_i2c\0off_i2c";
			pinctrl-0 = <0x08>;
			pinctrl-1 = <0x09>;
			pinctrl-2 = <0x08>;

			is-3h1@35 {
				compatible = "samsung,exynos-is-cis-3h1";
				sensor-module = <0x0a>;
				reg = <0x35>;
				id = <0x01>;
				setfile = "setA";
				status = "okay";
			};
		};
	};

	fragment@5 {
		target = <0xffffffff>;

		__overlay__ {
			#address-cells = <0x01>;
			#size-cells = <0x00>;
			gpios = <0xffffffff 0x00 0x00 0xffffffff 0x00 0x00>;
			status = "okay";
			clock-frequency = <0xf4240>;
			samsung,reset-before-trans;
			samsung,fast-plus-mode;
			pinctrl-names = "default\0on_i2c\0off_i2c";
			pinctrl-0 = <0x0b>;
			pinctrl-1 = <0x0c>;
			pinctrl-2 = <0x0b>;
		};
	};

	fragment@6 {
		target = <0xffffffff>;

		__overlay__ {
			#address-cells = <0x01>;
			#size-cells = <0x00>;
			gpios = <0xffffffff 0x00 0x00 0xffffffff 0x00 0x00>;
			status = "okay";
			clock-frequency = <0xf4240>;
			samsung,reset-before-trans;
			samsung,fast-plus-mode;
			pinctrl-names = "default\0on_i2c\0off_i2c";
			pinctrl-0 = <0x0d>;
			pinctrl-1 = <0x0e>;
			pinctrl-2 = <0x0d>;

			is-actuator@0C {
				compatible = "samsung,exynos-is-actuator-ak737x";
				sensor-module = <0x03>;
				reg = <0x0f>;
				id = <0x02>;
				vendor_product_id = <0xf3 0x0e 0xf3 0x13 0xf3 0x00>;
				vendor_first_pos = <0xfa>;
				vendor_first_delay = <0x7d0>;
				vendor_soft_landing_seqid = <0x01>;
				vendor_soft_landing_list = <0x64 0x1e 0x00 0x1e>;
				vendor_use_sleep_mode;
				vendor_use_standby_mode;
				status = "okay";
			};
		};
	};

	fragment@7 {
		target = <0xffffffff>;

		__overlay__ {
			#address-cells = <0x01>;
			#size-cells = <0x00>;
			gpios = <0xffffffff 0x00 0x00 0xffffffff 0x00 0x00>;
			status = "okay";
			clock-frequency = <0xf4240>;
			samsung,reset-before-trans;
			samsung,fast-plus-mode;
			pinctrl-names = "default\0on_i2c\0off_i2c";
			pinctrl-0 = <0x0f>;
			pinctrl-1 = <0x10>;
			pinctrl-2 = <0x0f>;

			is-actuator@0C {
				compatible = "samsung,exynos-is-actuator-ak737x";
				sensor-module = <0x0a>;
				reg = <0x0c>;
				id = <0x01>;
				vendor_product_id = <0xf3 0x0e 0xf3 0x13 0xf3 0x00>;
				vendor_first_pos = <0x78>;
				vendor_first_delay = <0x7d0>;
				vendor_use_sleep_mode;
				status = "okay";
			};
		};
	};

	fragment@8 {
		target = <0xffffffff>;

		__overlay__ {

			vender {

				sensor_name {
					0 = "2LA";
					1 = "3H1";
					2 = "GW2";
				};
			};

			is_dvfs {

				table0 {
					desc = "dvfs table v0.2";
					default_csis = <0x01>;
					default_cam = <0x01>;
					default_isp = <0x01>;
					default_m2m = <0x01>;
					default_mif = <0x03>;
					default_int = <0x01>;
					default_cpu = "0-5";
					rear_single_photo_isp = <0x06>;
					rear_single_photo_mif = <0x06>;
					rear_single_photo_int = <0x05>;
					rear_single_photo_cpu = "0-5";
					rear_single_photo_full_mif = <0x06>;
					rear_single_photo_full_int = <0x03>;
					rear_single_photo_full_cpu = "0-5";
					rear_single_video_hd30_isp = <0x06>;
					rear_single_video_hd30_mif = <0x06>;
					rear_single_video_hd30_int = <0x05>;
					rear_single_video_hd30_cpu = "0-5";
					rear_single_video_fhd30_isp = <0x06>;
					rear_single_video_fhd30_mif = <0x06>;
					rear_single_video_fhd30_int = <0x05>;
					rear_single_video_fhd30_cpu = "0-5";
					rear_single_video_fhd60_isp = <0x06>;
					rear_single_video_fhd60_mif = <0x03>;
					rear_single_video_fhd60_int = <0x04>;
					rear_single_video_fhd60_cpu = "0-5";
					rear_single_video_uhd30_isp = <0x06>;
					rear_single_video_uhd30_mif = <0x04>;
					rear_single_video_uhd30_int = <0x03>;
					rear_single_video_uhd30_cpu = "0-5";
					rear_single_capture_cam = <0x00>;
					rear_single_capture_isp = <0x04>;
					rear_single_capture_mif = <0x03>;
					rear_single_capture_int = <0x03>;
					rear_single_capture_cpu = "0-5";
					rear_single_video_fhd120_isp = <0x06>;
					rear_single_video_fhd120_m2m = <0x05>;
					rear_single_video_fhd120_mif = <0x03>;
					rear_single_video_fhd120_int = <0x03>;
					rear_single_video_fhd120_cpu = "0-5";
					rear_single_video_hd240_isp = <0x06>;
					rear_single_video_hd240_m2m = <0x05>;
					rear_single_video_hd240_mif = <0x03>;
					rear_single_video_hd240_int = <0x03>;
					rear_single_video_hd240_cpu = "0-5";
					rear_single_ssm_isp = <0x06>;
					rear_single_ssm_m2m = <0x05>;
					rear_single_ssm_mif = <0x03>;
					rear_single_ssm_int = <0x03>;
					rear_single_ssm_hpg = <0x06>;
					rear_single_ssm_cpu = "0-5";
					rear_single_vt_isp = <0x00>;
					rear_single_vt_mif = <0x03>;
					rear_single_vt_int = <0x00>;
					rear_single_vt_cpu = "0-5";
					rear_single_video_fhd30_supersteady_isp = <0x06>;
					rear_single_video_fhd30_supersteady_mif = <0x06>;
					rear_single_video_fhd30_supersteady_int = <0x05>;
					rear_single_video_fhd30_supersteady_cpu = "0-5";
					rear_single_remosaic_photo_isp = <0x00>;
					rear_single_remosaic_photo_mif = <0x03>;
					rear_single_remosaic_photo_int = <0x00>;
					rear_single_remosaic_photo_cpu = "0-5";
					rear_single_remosaic_capture_cam = <0x00>;
					rear_single_remosaic_capture_isp = <0x03>;
					rear_single_remosaic_capture_mif = <0x03>;
					rear_single_remosaic_capture_int = <0x03>;
					rear_single_remosaic_capture_cpu = "0-5";
					rear_dual_wide_tele_photo_isp = <0x06>;
					rear_dual_wide_tele_photo_mif = <0x05>;
					rear_dual_wide_tele_photo_int = <0x05>;
					rear_dual_wide_tele_photo_cpu = "0-5";
					rear_dual_wide_tele_video_fhd30_isp = <0x00>;
					rear_dual_wide_tele_video_fhd30_mif = <0x03>;
					rear_dual_wide_tele_video_fhd30_int = <0x00>;
					rear_dual_wide_tele_video_fhd30_cpu = "0-5";
					rear_dual_wide_tele_video_uhd30_isp = <0x00>;
					rear_dual_wide_tele_video_uhd30_mif = <0x03>;
					rear_dual_wide_tele_video_uhd30_int = <0x00>;
					rear_dual_wide_tele_video_uhd30_cpu = "0-5";
					rear_dual_wide_tele_video_fhd60_isp = <0x00>;
					rear_dual_wide_tele_video_fhd60_mif = <0x03>;
					rear_dual_wide_tele_video_fhd60_int = <0x00>;
					rear_dual_wide_tele_video_fhd60_cpu = "0-5";
					rear_dual_wide_tele_capture_cam = <0x00>;
					rear_dual_wide_tele_capture_isp = <0x03>;
					rear_dual_wide_tele_capture_mif = <0x04>;
					rear_dual_wide_tele_capture_int = <0x05>;
					rear_dual_wide_tele_capture_cpu = "0-5";
					rear_dual_wide_ultrawide_photo_isp = <0x00>;
					rear_dual_wide_ultrawide_photo_mif = <0x03>;
					rear_dual_wide_ultrawide_photo_int = <0x00>;
					rear_dual_wide_ultrawide_photo_cpu = "0-5";
					rear_dual_wide_ultrawide_video_fhd30_isp = <0x00>;
					rear_dual_wide_ultrawide_video_fhd30_mif = <0x03>;
					rear_dual_wide_ultrawide_video_fhd30_int = <0x00>;
					rear_dual_wide_ultrawide_video_fhd30_cpu = "0-5";
					rear_dual_wide_ultrawide_video_uhd30_isp = <0x00>;
					rear_dual_wide_ultrawide_video_uhd30_mif = <0x03>;
					rear_dual_wide_ultrawide_video_uhd30_int = <0x00>;
					rear_dual_wide_ultrawide_video_uhd30_cpu = "0-5";
					rear_dual_wide_ultrawide_video_fhd60_isp = <0x00>;
					rear_dual_wide_ultrawide_video_fhd60_mif = <0x03>;
					rear_dual_wide_ultrawide_video_fhd60_int = <0x00>;
					rear_dual_wide_ultrawide_video_fhd60_cpu = "0-5";
					rear_dual_wide_ultrawide_capture_cam = <0x00>;
					rear_dual_wide_ultrawide_capture_isp = <0x00>;
					rear_dual_wide_ultrawide_capture_mif = <0x03>;
					rear_dual_wide_ultrawide_capture_int = <0x00>;
					rear_dual_wide_ultrawide_capture_cpu = "0-5";
					front_single_photo_isp = <0x06>;
					front_single_photo_mif = <0x07>;
					front_single_photo_int = <0x05>;
					front_single_photo_cpu = "0-5";
					front_single_photo_full_mif = <0x03>;
					front_single_photo_full_int = <0x04>;
					front_single_photo_full_cpu = "0-5";
					front_single_video_hd30_isp = <0x06>;
					front_single_video_hd30_mif = <0x06>;
					front_single_video_hd30_int = <0x05>;
					front_single_video_hd30_cpu = "0-5";
					front_single_video_fhd30_isp = <0x06>;
					front_single_video_fhd30_mif = <0x06>;
					front_single_video_fhd30_int = <0x05>;
					front_single_video_fhd30_cpu = "0-5";
					front_single_video_uhd30_isp = <0x06>;
					front_single_video_uhd30_mif = <0x05>;
					front_single_video_uhd30_int = <0x03>;
					front_single_video_uhd30_cpu = "0-5";
					front_single_video_fhd60_isp = <0x00>;
					front_single_video_fhd60_mif = <0x03>;
					front_single_video_fhd60_int = <0x00>;
					front_single_video_fhd60_cpu = "0-5";
					front_single_capture_cam = <0x04>;
					front_single_capture_isp = <0x06>;
					front_single_capture_mif = <0x03>;
					front_single_capture_int = <0x04>;
					front_single_capture_cpu = "0-5";
					front_single_vt_isp = <0x00>;
					front_single_vt_mif = <0x03>;
					front_single_vt_int = <0x00>;
					front_single_vt_cpu = "0-5";
					front_single_video_fhd120_isp = <0x00>;
					front_single_video_fhd120_mif = <0x00>;
					front_single_video_fhd120_int = <0x03>;
					front_single_video_fhd120_hpg = <0x00>;
					front_single_video_fhd120_cpu = "0-5";
					rear_single_wide_fastae_cam = <0x01>;
					rear_single_wide_fastae_isp = <0x01>;
					rear_single_wide_fastae_m2m = <0x01>;
					rear_single_wide_fastae_mif = <0x03>;
					rear_single_wide_fastae_int = <0x01>;
					rear_single_wide_fastae_cpu = "0-5";
					front_single_fastae_cam = <0x01>;
					front_single_fastae_csis = <0x01>;
					front_single_fastae_isp = <0x01>;
					front_single_fastae_m2m = <0x01>;
					front_single_fastae_mif = <0x03>;
					front_single_fastae_int = <0x01>;
					front_single_fastae_cpu = "0-5";
					pip_dual_photo_isp = <0x06>;
					pip_dual_photo_mif = <0x04>;
					pip_dual_photo_int = <0x05>;
					pip_dual_photo_cpu = "0-5";
					pip_dual_capture_cam = <0x00>;
					pip_dual_capture_isp = <0x01>;
					pip_dual_capture_mif = <0x03>;
					pip_dual_capture_int = <0x05>;
					pip_dual_capture_cpu = "0-5";
					pip_dual_video_fhd30_isp = <0x01>;
					pip_dual_video_fhd30_mif = <0x03>;
					pip_dual_video_fhd30_int = <0x04>;
					pip_dual_video_fhd30_cpu = "0-5";
					sensor_only_rear_single_cam = <0x01>;
					sensor_only_rear_single_csis = <0x01>;
					sensor_only_rear_single_isp = <0x01>;
					sensor_only_rear_single_m2m = <0x01>;
					sensor_only_rear_single_mif = <0x03>;
					sensor_only_rear_single_int = <0x01>;
					sensor_only_rear_single_cpu = "0-5";
					sensor_only_front_cam = <0x01>;
					sensor_only_front_csis = <0x01>;
					sensor_only_front_isp = <0x01>;
					sensor_only_front_m2m = <0x01>;
					sensor_only_front_mif = <0x03>;
					sensor_only_front_int = <0x01>;
					sensor_only_front_cpu = "0-5";
					throttling_cam = <0x00>;
					throttling_csis = <0x00>;
					throttling_isp = <0x00>;
					throttling_m2m = <0x00>;
					throttling_mif = <0x03>;
					throttling_int = <0x00>;
					throttling_hpg = <0x00>;
					throttling_cpu = "0-5";
					max_cam = <0x01>;
					max_csis = <0x01>;
					max_isp = <0x01>;
					max_m2m = <0x01>;
					max_mif = <0x03>;
					max_int = <0x01>;
					max_cpu = "0-5";
				};
			};
		};
	};

	fragment@9 {
		target = <0xffffffff>;

		__overlay__ {

			but_zones {
				#list-but-cells = <0x02>;
				phandle = <0x18>;
			};

			imp_range {
				#list-imp-cells = <0x05>;
				phandle = <0x16>;
			};

			mic_range {
				#list-imp-cells = <0x02>;
				phandle = <0x15>;
			};

			wtp_range {
				#list-ldet-cells = <0x03>;
				phandle = <0x17>;
			};
		};
	};

	fragment@10 {
		target = <0xffffffff>;

		__overlay__ {

			s5m3700x-irq {
				samsung,pins = "gpa0-6";
				samsung,pin-function = <0x0f>;
				samsung,pin-pud = <0x03>;
				samsung,pin-drv = <0x00>;
				phandle = <0x14>;
			};

			s5m3700x_external_ldo_1_8v {
				samsung,pins = "gpc8-0";
				samsung,pin-function = <0x01>;
				samsung,pin-pud = <0x01>;
				samsung,pin-drv = <0x00>;
				samsung,pin-con-pdn = <0x03>;
				samsung,pin-pud-pdn = <0x01>;
				phandle = <0x12>;
			};
		};
	};

	fragment@11 {
		target = <0xffffffff>;

		__overlay__ {

			s5m3700x_resetb {
				samsung,pins = "gpp2-6";
				samsung,pin-function = <0x01>;
				samsung,pin-pud = <0x01>;
				samsung,pin-drv = <0x00>;
				samsung,pin-con-pdn = <0x03>;
				samsung,pin-pud-pdn = <0x01>;
				phandle = <0x11>;
			};

			s5m3700x_external_ldo_3_4v {
				samsung,pins = "gpp2-7";
				samsung,pin-function = <0x01>;
				samsung,pin-pud = <0x01>;
				samsung,pin-drv = <0x00>;
				samsung,pin-con-pdn = <0x03>;
				samsung,pin-pud-pdn = <0x01>;
				phandle = <0x13>;
			};
		};
	};

	fragment@12 {
		target = <0xffffffff>;

		__overlay__ {
			#address-cells = <0x01>;
			#size-cells = <0x00>;
			status = "okay";
			clock-frequency = <0x61a80>;

			s5m3700x@14 {
				status = "okay";
				compatible = "samsung,s5m3700x";
				#sound-dai-cells = <0x00>;
				reg = <0x14>;
				pinctrl-names = "default";
				pinctrl-0 = <0x11 0x12 0x13 0x14>;
				s5m3700x-resetb = <0xffffffff 0x06 0x01>;
				s5m3700x-external-ldo-1-8v = <0xffffffff 0x00 0x01>;
				s5m3700x-external-ldo-3-4v = <0xffffffff 0x07 0x01>;
				s5m3700x-power-always-on;
				s5m3700x-codec-int = <0xffffffff 0x06 0x00>;
				s5m3700x-rcv_imp = <0x00>;
				jack-type = <0x00>;
				mic-bias1-voltage = <0x05>;
				mic-bias2-voltage = <0x0f>;
				mic-bias3-voltage = <0x05>;
				mic-adc-range = <0x15 0x460 0xfa0>;
				jack-imp-range = <0x16 0x01 0x06 0x21 0x33 0x6f>;
				wtp-ldet-range = <0x17 0x258 0x3e8 0xe70>;
				but-zones-list = <0x18 0x00 0x75 0x18 0xaf 0x118 0x18 0x13b 0x1ae 0x18 0x1f9 0x357>;
				phandle = <0x20>;
			};
		};
	};

	fragment@13 {
		target = <0xffffffff>;

		__overlay__ {

			pm-wrstbi {
				samsung,pins = "gpc1-0";
				samsung,pin-con-pdn = <0x03>;
				samsung,pin-pud-pdn = <0x00>;
				phandle = <0x19>;
			};
		};
	};

	fragment@14 {
		target = <0xffffffff>;

		__overlay__ {

			smpl-warn {
				samsung,pins = "gpg0-0";
				samsung,pin-function = <0x0f>;
				samsung,pin-pud = <0x00>;
				samsung,pin-drv = <0x00>;
				samsung,pin-con-pdn = <0x02>;
				samsung,pin-pud-pdn = <0x00>;
				phandle = <0x1a>;
			};
		};
	};

	fragment@15 {
		target = <0xffffffff>;

		__overlay__ {
			status = "okay";
			#address-cells = <0x01>;
			#size-cells = <0x00>;

			s2mpu15mfd@1f {
				compatible = "samsung,s2mpu15mfd";
				acpm-ipc-channel = <0x02>;
				s2mpu15,wakeup = "enabled";
				reg = <0x1f>;
				interrupts = <0x00 0x20 0x04>;
				interrupt-parent = <0xffffffff>;
				pinctrl-names = "default";
				pinctrl-0 = <0x19 0x1a>;
				gpios = <0xffffffff 0x00 0x00>;
				wtsr_en = "enabled";
				smpl_en = "enabled";
				wtsr_timer_val = <0x03>;
				smpl_timer_val = <0x00>;
				check_jigon = <0x00>;
				init_time,sec = <0x00>;
				init_time,min = <0x00>;
				init_time,hour = <0x0c>;
				init_time,mday = <0x01>;
				init_time,mon = <0x00>;
				init_time,year = <0x7a>;
				init_time,wday = <0x06>;
				smpl_warn_en = <0x01>;

				s2mpu15-gpadc {
					#io-channel-cells = <0x01>;
					io-channel-ranges;
					acpm-ipc-channel = <0x0b>;
					phandle = <0x40>;
				};

				s2mpu15-keys {

					button@1 {
						label = "pmic-keys: KEY_POWER";
						linux,code = <0x74>;
						wakeup;
					};

					button@2 {
						label = "pmic-keys: KEY_VOLUMEDOWN";
						linux,code = <0x72>;
					};
				};

				s2mpu15-gpio {
					gpio-controller;
					#gpio-cells = <0x02>;
					samsung,npins = <0x02>;
					status = "okay";
					phandle = <0x41>;
				};

				regulators {

					BUCK1 {
						regulator-name = "vdd_sram";
						regulator-min-microvolt = <0x61a80>;
						regulator-max-microvolt = <0x13d620>;
						regulator-ramp-delay = <0x1770>;
						regulator-initial-mode = <0x01>;
						regulator-always-on;
						phandle = <0x42>;
					};

					BUCK2 {
						regulator-name = "vdd_cpu_cp";
						regulator-min-microvolt = <0x61a80>;
						regulator-max-microvolt = <0x13d620>;
						regulator-ramp-delay = <0x1770>;
						regulator-initial-mode = <0x01>;
						regulator-always-on;
						phandle = <0x43>;
					};

					BUCK3 {
						regulator-name = "vdd_cam";
						regulator-min-microvolt = <0x61a80>;
						regulator-max-microvolt = <0x13d620>;
						regulator-ramp-delay = <0x1770>;
						regulator-initial-mode = <0x01>;
						regulator-always-on;
						phandle = <0x44>;
					};

					BUCK4 {
						regulator-name = "vdd_cpucl0_lit";
						regulator-min-microvolt = <0x61a80>;
						regulator-max-microvolt = <0x13d620>;
						regulator-ramp-delay = <0x1770>;
						regulator-initial-mode = <0x01>;
						regulator-always-on;
						phandle = <0x45>;
					};

					BUCK5 {
						regulator-name = "vdd_cpucl1_big1";
						regulator-min-microvolt = <0x61a80>;
						regulator-max-microvolt = <0x13d620>;
						regulator-ramp-delay = <0x1770>;
						regulator-initial-mode = <0x01>;
						regulator-always-on;
						phandle = <0x46>;
					};

					BUCK6 {
						regulator-name = "vdd_cpucl1_big2";
						regulator-min-microvolt = <0x61a80>;
						regulator-max-microvolt = <0x13d620>;
						regulator-ramp-delay = <0x1770>;
						regulator-initial-mode = <0x01>;
						regulator-always-on;
						phandle = <0x47>;
					};

					BUCK7 {
						regulator-name = "vdd_int";
						regulator-min-microvolt = <0x61a80>;
						regulator-max-microvolt = <0x13d620>;
						regulator-ramp-delay = <0x1770>;
						regulator-initial-mode = <0x01>;
						regulator-always-on;
						phandle = <0x48>;
					};

					BUCK8 {
						regulator-name = "vdd2h_mem";
						regulator-min-microvolt = <0x61a80>;
						regulator-max-microvolt = <0x13d620>;
						regulator-ramp-delay = <0x1770>;
						regulator-initial-mode = <0x03>;
						regulator-always-on;
						phandle = <0x49>;
					};

					BUCK_SR1 {
						regulator-name = "vdd_0.75v_ldos";
						regulator-min-microvolt = <0x927c0>;
						regulator-max-microvolt = <0x149970>;
						regulator-ramp-delay = <0x1770>;
						regulator-initial-mode = <0x03>;
						regulator-always-on;
						phandle = <0x4a>;
					};

					BUCK_SR2 {
						regulator-name = "vdd_0.85v_ldos";
						regulator-min-microvolt = <0x927c0>;
						regulator-max-microvolt = <0x149970>;
						regulator-ramp-delay = <0x1770>;
						regulator-initial-mode = <0x03>;
						regulator-always-on;
						phandle = <0x4b>;
					};

					BUCK_SR3 {
						regulator-name = "vdd_1.20v_ldos";
						regulator-min-microvolt = <0x927c0>;
						regulator-max-microvolt = <0x149970>;
						regulator-ramp-delay = <0x1770>;
						regulator-initial-mode = <0x03>;
						regulator-always-on;
						phandle = <0x4c>;
					};

					BUCK_SR4 {
						regulator-name = "vdd_1.80v_ldos";
						regulator-min-microvolt = <0x1ab3f0>;
						regulator-max-microvolt = <0x1e8480>;
						regulator-ramp-delay = <0x1770>;
						regulator-initial-mode = <0x03>;
						regulator-always-on;
						phandle = <0x4d>;
					};

					LDO1 {
						regulator-name = "vdd_ldo1";
						regulator-min-microvolt = <0x61a80>;
						regulator-max-microvolt = <0x13d620>;
						regulator-ramp-delay = <0x2ee0>;
						regulator-initial-mode = <0x03>;
						regulator-always-on;
						phandle = <0x4e>;
					};

					LDO2 {
						regulator-name = "vqmmc";
						regulator-min-microvolt = <0x1b7740>;
						regulator-max-microvolt = <0x337f98>;
						regulator-ramp-delay = <0x2ee0>;
						regulator-initial-mode = <0x03>;
						phandle = <0x4f>;
					};

					LDO3 {
						regulator-name = "vdd_ldo3";
						regulator-min-microvolt = <0x61a80>;
						regulator-max-microvolt = <0x13d620>;
						regulator-ramp-delay = <0x2ee0>;
						regulator-initial-mode = <0x01>;
						regulator-always-on;
						phandle = <0x50>;
					};

					LDO4 {
						regulator-name = "vdd_ldo4";
						regulator-min-microvolt = <0x186a00>;
						regulator-max-microvolt = <0x1dc130>;
						regulator-ramp-delay = <0x2ee0>;
						regulator-initial-mode = <0x01>;
						regulator-always-on;
						phandle = <0x51>;
					};

					LDO5 {
						regulator-name = "vdd_ldo5";
						regulator-min-microvolt = <0x61a80>;
						regulator-max-microvolt = <0x13d620>;
						regulator-ramp-delay = <0x2ee0>;
						regulator-initial-mode = <0x01>;
						regulator-always-on;
						phandle = <0x52>;
					};

					LDO6 {
						regulator-name = "vdd33_usb";
						regulator-min-microvolt = <0x1b7740>;
						regulator-max-microvolt = <0x337f98>;
						regulator-ramp-delay = <0x2ee0>;
						regulator-initial-mode = <0x03>;
						phandle = <0x28>;
					};

					LDO7 {
						regulator-name = "vdd_ldo7";
						regulator-min-microvolt = <0x186a00>;
						regulator-max-microvolt = <0x1dc130>;
						regulator-ramp-delay = <0x2ee0>;
						regulator-initial-mode = <0x03>;
						regulator-always-on;
						phandle = <0x53>;
					};

					LDO16 {
						regulator-name = "vdd_ldo16";
						regulator-min-microvolt = <0x186a00>;
						regulator-max-microvolt = <0x1dc130>;
						regulator-ramp-delay = <0x2ee0>;
						regulator-initial-mode = <0x03>;
						regulator-always-on;
						phandle = <0x54>;
					};

					LDO17 {
						regulator-name = "vdd_ldo17";
						regulator-min-microvolt = <0x61a80>;
						regulator-max-microvolt = <0x13d620>;
						regulator-always-on;
						regulator-ramp-delay = <0x2ee0>;
						regulator-initial-mode = <0x03>;
						phandle = <0x55>;
					};

					LDO18 {
						regulator-name = "vdd_ldo18";
						regulator-min-microvolt = <0x186a00>;
						regulator-max-microvolt = <0x1dc130>;
						regulator-ramp-delay = <0x2ee0>;
						regulator-initial-mode = <0x03>;
						regulator-always-on;
						phandle = <0x56>;
					};

					LDO19 {
						regulator-name = "vdd_ldo19";
						regulator-min-microvolt = <0x61a80>;
						regulator-max-microvolt = <0x13d620>;
						regulator-ramp-delay = <0x2ee0>;
						regulator-initial-mode = <0x01>;
						regulator-always-on;
						phandle = <0x57>;
					};

					LDO25 {
						regulator-name = "vdd_ldo25";
						regulator-min-microvolt = <0x61a80>;
						regulator-max-microvolt = <0x13d620>;
						regulator-ramp-delay = <0x2ee0>;
						regulator-initial-mode = <0x03>;
						regulator-always-on;
						phandle = <0x58>;
					};

					LDO28 {
						regulator-name = "vdd_ldo28";
						regulator-min-microvolt = <0x1b7740>;
						regulator-max-microvolt = <0x1dc130>;
						regulator-ramp-delay = <0x2ee0>;
						regulator-initial-mode = <0x03>;
						regulator-always-on;
						phandle = <0x59>;
					};

					LDO29 {
						regulator-name = "vdd_ldo29";
						regulator-min-microvolt = <0x1b7740>;
						regulator-max-microvolt = <0x337f98>;
						regulator-ramp-delay = <0x2ee0>;
						regulator-initial-mode = <0x03>;
						phandle = <0x26>;
					};

					LDO30 {
						regulator-name = "vdd_ldo30";
						regulator-min-microvolt = <0x1b7740>;
						regulator-max-microvolt = <0x1dc130>;
						regulator-ramp-delay = <0x2ee0>;
						regulator-initial-mode = <0x03>;
						phandle = <0x27>;
					};

					LDO31 {
						regulator-name = "vdd_ldo31";
						regulator-min-microvolt = <0x61a80>;
						regulator-max-microvolt = <0x13d620>;
						regulator-ramp-delay = <0x2ee0>;
						regulator-initial-mode = <0x03>;
						regulator-always-on;
						phandle = <0x5a>;
					};

					LDO32 {
						regulator-name = "vdd_ldo32";
						regulator-min-microvolt = <0x1b7740>;
						regulator-max-microvolt = <0x337f98>;
						regulator-ramp-delay = <0x2ee0>;
						regulator-initial-mode = <0x03>;
						regulator-always-on;
						phandle = <0x5b>;
					};

					LDO33 {
						regulator-name = "vdd_ldo33";
						regulator-min-microvolt = <0x1b7740>;
						regulator-max-microvolt = <0x337f98>;
						regulator-ramp-delay = <0x2ee0>;
						regulator-initial-mode = <0x03>;
						phandle = <0x5c>;
					};

					LDO34 {
						regulator-name = "vdd_ldo34";
						regulator-min-microvolt = <0x61a80>;
						regulator-max-microvolt = <0x13d620>;
						regulator-ramp-delay = <0x2ee0>;
						regulator-initial-mode = <0x01>;
						regulator-always-on;
						phandle = <0x5d>;
					};

					LDO35 {
						regulator-name = "vdd_ldo35";
						regulator-min-microvolt = <0x61a80>;
						regulator-max-microvolt = <0x13d620>;
						regulator-ramp-delay = <0x2ee0>;
						regulator-initial-mode = <0x01>;
						regulator-always-on;
						phandle = <0x5e>;
					};
				};
			};
		};
	};

	fragment@16 {
		target = <0xffffffff>;

		__overlay__ {
			status = "okay";
			#address-cells = <0x01>;
			#size-cells = <0x00>;

			s2mpa05mfd@2f {
				compatible = "samsung,s2mpa05mfd";
				acpm-ipc-channel = <0x02>;
				s2mpa05,wakeup = "enabled";
				reg = <0x2f>;
				wtsr_en = <0x01>;

				s2mpa05-gpio {
					gpio-controller;
					#gpio-cells = <0x02>;
					samsung,npins = <0x02>;
					status = "okay";
					phandle = <0x5f>;
				};

				regulators {

					BUCK3 {
						regulator-name = "vdd_g3d";
						regulator-min-microvolt = <0x61a80>;
						regulator-max-microvolt = <0x13d620>;
						regulator-ramp-delay = <0x1770>;
						regulator-initial-mode = <0x01>;
						regulator-always-on;
						phandle = <0x60>;
					};

					LDO2 {
						regulator-name = "vdd_ldo2s";
						regulator-min-microvolt = <0x1b7740>;
						regulator-max-microvolt = <0x337f98>;
						regulator-ramp-delay = <0x2ee0>;
						regulator-initial-mode = <0x03>;
						regulator-always-on;
						phandle = <0x61>;
					};

					LDO3 {
						regulator-name = "vmmc";
						regulator-min-microvolt = <0x1b7740>;
						regulator-max-microvolt = <0x337f98>;
						regulator-ramp-delay = <0x2ee0>;
						regulator-initial-mode = <0x03>;
						phandle = <0x62>;
					};
				};
			};
		};
	};

	fragment@model {
		target-path = "/";

		__overlay__ {
			#address-cells = <0x02>;
			#size-cells = <0x01>;
			model = "Samsung ERD8535 board based on S5E8535";

			gpio_keys {
				status = "okay";
				compatible = "gpio-keys";
				pinctrl-names = "default";
				pinctrl-0 = <0x1b 0x1c>;

				button@3 {
					label = "gpio-keys: KEY_VOLUMEUP";
					linux,code = <0x73>;
					gpios = <0xffffffff 0x00 0x0f>;
				};
			};

			hs_tune {
				hs_tune_cnt = <0x07>;
				phandle = <0x29>;

				hs_tune1 {
					tune_name = "tx_pre_emp";
					tune_value = <0x03 0x03>;
				};

				hs_tune2 {
					tune_name = "tx_vref";
					tune_value = <0x0d 0x0d>;
				};

				hs_tune3 {
					tune_name = "rx_sqrx";
					tune_value = <0x07 0x07>;
				};

				hs_tune4 {
					tune_name = "utmi_clk";
					tune_value = <0x01 0x01>;
				};

				hs_tune5 {
					tune_name = "compdis";
					tune_value = <0x07 0x07>;
				};

				hs_tune6 {
					tune_name = "tx_res";
					tune_value = <0x01 0x01>;
				};

				hs_tune7 {
					tune_name = "tx_rise";
					tune_value = <0x01 0x01>;
				};
			};

			usb_notifier {
				compatible = "samsung,usb-notifier";
				udc = <0xffffffff>;
				status = "okay";
			};

			gnss_mailbox {
				status = "okay";
				compatible = "samsung,exynos-gnss-mailbox";
				reg = <0x00 0x11a50000 0x200>;
				interrupt-parent = <0xffffffff>;
				interrupts = <0x00 0x2d 0x04>;
				mbox,name = "gnss_mailbox";
				mbox,id = <0x00>;
				num_shared_reg = <0x04>;
				shared_reg_offset = <0x100>;
				use_sw_reset_reg = <0x00>;
				phandle = <0x1d>;
			};

			gnssif {
				status = "okay";
				compatible = "samsung,exynos-gnss";
				interrupt-parent = <0xffffffff>;
				interrupts = <0x00 0x1c 0x04 0x00 0x11b 0x04 0x00 0x11a 0x04 0x00 0x119 0x01>;
				interrupt-names = "ACTIVE\0WATCHDOG\0WAKEUP\0SW_INIT";
				shmem,name = "KEPLER";
				device_node_name = "gnss_ipc";
				mbox_info = <0x1d>;
				mbx,int_bcmd = <0x00>;
				mbx,int_req_fault_info = <0x01>;
				mbx,int_ipc_msg = <0x02>;
				mbx,int_ack_wake_set = <0x03>;
				mbx,int_ack_wake_clr = <0x04>;
				mbx,irq_bcmd = <0x00>;
				mbx,irq_rsp_fault_info = <0x01>;
				mbx,irq_ipc_msg = <0x02>;
				mbx,irq_req_wake_clr = <0x04>;
				mbx,irq_simple_lock = <0x0f>;
				mbx,reg_bcmd_ctrl = <0x00 0x01 0x02 0x03>;
				memory-region = <0xffffffff>;
				reg_rx_ipc_msg = <0x01 0x05>;
				reg_tx_ipc_msg = <0x01 0x04>;
				reg_rx_head = <0x01 0x03>;
				reg_rx_tail = <0x01 0x02>;
				reg_tx_head = <0x01 0x01>;
				reg_tx_tail = <0x01 0x00>;
				fault_info = <0x01 0x200000 0x180000>;
				shmem,code_offset = <0x00>;
				shmem,code_allowed_size = <0x380000>;
				shmem,ipc_offset = <0x380000>;
				shmem,ipc_size = <0x80000>;
				shmem,ipc_rx_offset = <0x00>;
				shmem,ipc_rx_size = <0x40000>;
				shmem,ipc_tx_offset = <0x40000>;
				shmem,ipc_tx_size = <0x3ff80>;
				shmem,ipc_reg_offset = <0x7ff80>;
				shmem,ipc_reg_size = <0x80>;

				baaw_configuration {
					window_cnt = <0x09>;

					window_0 {
						baaw,sfr_addr = <0x13fe0000>;
						baaw,start = <0xb19c0>;
						baaw,end = <0xb19d0>;
						baaw,ap_start = <0x119c0>;
						baaw,authority = <0x80000003>;
					};

					window_1 {
						baaw,sfr_addr = <0x13fe0010>;
						baaw,start = <0xb1a40>;
						baaw,end = <0xb1a50>;
						baaw,ap_start = <0x11a40>;
						baaw,authority = <0x80000003>;
					};

					window_2 {
						baaw,sfr_addr = <0x13fe0020>;
						baaw,start = <0xb1a50>;
						baaw,end = <0xb1a60>;
						baaw,ap_start = <0x11a50>;
						baaw,authority = <0x80000003>;
					};

					window_3 {
						baaw,sfr_addr = <0x13fe0030>;
						baaw,start = <0xb18e0>;
						baaw,end = <0xb18f0>;
						baaw,ap_start = <0x118e0>;
						baaw,authority = <0x80000003>;
					};

					window_4 {
						baaw,sfr_addr = <0x13fe0040>;
						baaw,start = <0xb1b80>;
						baaw,end = <0xb1b90>;
						baaw,ap_start = <0x11b80>;
						baaw,authority = <0x80000003>;
					};

					window_5 {
						baaw,sfr_addr = <0x13fe0050>;
						baaw,start = <0x60000>;
						baaw,end = <0x60600>;
						baaw,ap_start = <0xee000>;
						baaw,authority = <0x80000003>;
					};

					window_6 {
						baaw,sfr_addr = <0x13fe0060>;
						baaw,start = <0xa0000>;
						baaw,end = <0xa0600>;
						baaw,ap_start = <0xee000>;
						baaw,authority = <0x80000003>;
					};

					window_7 {
						baaw,sfr_addr = <0x13fe0070>;
						baaw,start = <0xb18f0>;
						baaw,end = <0xb1900>;
						baaw,ap_start = <0x118f0>;
						baaw,authority = <0x80000003>;
					};

					window_8 {
						baaw,sfr_addr = <0x13fe0080>;
						baaw,start = <0xb1a0f>;
						baaw,end = <0xb1a10>;
						baaw,ap_start = <0x1123f>;
						baaw,authority = <0x80000003>;
					};
				};
			};

			vbat {
				compatible = "regulator-fixed";
				regulator-name = "VBAT";
				regulator-min-microvolt = <0x401640>;
				regulator-max-microvolt = <0x401640>;
				regulator-boot-on;
				phandle = <0x23>;
			};

			audio-codec-dummy {
				compatible = "snd-soc-dummy";
				#sound-dai-cells = <0x00>;
				phandle = <0x63>;
			};

			audio-cpu-dummy {
				compatible = "samsung,dummy-cpu";
				#sound-dai-cells = <0x00>;
				phandle = <0x64>;
			};

			sound {
				compatible = "samsung,exynos-sound";
				samsung,routing = "RECEIVER\0Left SPK\0SPEAKER\0Right SPK\0BLUETOOTH SPK\0ABOX UAIF3 Playback\0ABOX UAIF3 Capture\0BLUETOOTH MIC\0USB SPK\0ABOX USB Playback\0ABOX USB Capture\0USB MIC\0FWD SPK\0ABOX FWD Playback\0ABOX FWD Capture\0FWD MIC\0VTS Virtual Output\0VTS Virtual Output Mux\0ABOX SPDY Capture\0VINPUT_FM";
				samsung,codec = <0x1e 0x1f>;
				samsung,prefix = "Left\0Right";
				samsung,aux = <0xffffffff 0xffffffff>;

				rdma0 {

					cpu {
						sound-dai = <0xffffffff 0x00>;
					};

					platform {
						sound-dai = <0xffffffff 0x00>;
					};
				};

				rdma1 {

					cpu {
						sound-dai = <0xffffffff 0x00>;
					};

					platform {
						sound-dai = <0xffffffff 0x00>;
					};
				};

				rdma2 {

					cpu {
						sound-dai = <0xffffffff 0x00>;
					};

					platform {
						sound-dai = <0xffffffff 0x00>;
					};
				};

				rdma3 {

					cpu {
						sound-dai = <0xffffffff 0x00>;
					};

					platform {
						sound-dai = <0xffffffff 0x00>;
					};
				};

				rdma4 {

					cpu {
						sound-dai = <0xffffffff 0x00>;
					};

					platform {
						sound-dai = <0xffffffff 0x00>;
					};
				};

				rdma5 {

					cpu {
						sound-dai = <0xffffffff 0x00>;
					};

					platform {
						sound-dai = <0xffffffff 0x00>;
					};
				};

				rdma6 {

					cpu {
						sound-dai = <0xffffffff 0x00>;
					};

					platform {
						sound-dai = <0xffffffff 0x00>;
					};
				};

				rdma7 {

					cpu {
						sound-dai = <0xffffffff 0x00>;
					};

					platform {
						sound-dai = <0xffffffff 0x00>;
					};
				};

				rdma8 {

					cpu {
						sound-dai = <0xffffffff 0x00>;
					};

					platform {
						sound-dai = <0xffffffff 0x00>;
					};
				};

				rdma9 {

					cpu {
						sound-dai = <0xffffffff 0x00>;
					};

					platform {
						sound-dai = <0xffffffff 0x00>;
					};
				};

				rdma10 {

					cpu {
						sound-dai = <0xffffffff 0x00>;
					};

					platform {
						sound-dai = <0xffffffff 0x00>;
					};
				};

				rdma11 {

					cpu {
						sound-dai = <0xffffffff 0x00>;
					};

					platform {
						sound-dai = <0xffffffff 0x00>;
					};
				};

				wdma0 {

					cpu {
						sound-dai = <0xffffffff 0x00>;
					};

					platform {
						sound-dai = <0xffffffff 0x00>;
					};
				};

				wdma1 {

					cpu {
						sound-dai = <0xffffffff 0x00>;
					};

					platform {
						sound-dai = <0xffffffff 0x00>;
					};
				};

				wdma2 {

					cpu {
						sound-dai = <0xffffffff 0x00>;
					};

					platform {
						sound-dai = <0xffffffff 0x00>;
					};
				};

				wdma3 {

					cpu {
						sound-dai = <0xffffffff 0x00>;
					};

					platform {
						sound-dai = <0xffffffff 0x00>;
					};
				};

				wdma4 {

					cpu {
						sound-dai = <0xffffffff 0x00>;
					};

					platform {
						sound-dai = <0xffffffff 0x00>;
					};
				};

				wdma5 {

					cpu {
						sound-dai = <0xffffffff 0x00>;
					};

					platform {
						sound-dai = <0xffffffff 0x00>;
					};
				};

				wdma6 {

					cpu {
						sound-dai = <0xffffffff 0x00>;
					};

					platform {
						sound-dai = <0xffffffff 0x00>;
					};
				};

				wdma7 {

					cpu {
						sound-dai = <0xffffffff 0x00>;
					};

					platform {
						sound-dai = <0xffffffff 0x00>;
					};
				};

				wdma8 {

					cpu {
						sound-dai = <0xffffffff 0x00>;
					};

					platform {
						sound-dai = <0xffffffff 0x00>;
					};
				};

				wdma9 {

					cpu {
						sound-dai = <0xffffffff 0x00>;
					};

					platform {
						sound-dai = <0xffffffff 0x00>;
					};
				};

				wdma10 {

					cpu {
						sound-dai = <0xffffffff 0x00>;
					};

					platform {
						sound-dai = <0xffffffff 0x00>;
					};
				};

				wdma11 {

					cpu {
						sound-dai = <0xffffffff 0x00>;
					};

					platform {
						sound-dai = <0xffffffff 0x00>;
					};
				};

				dual0 {

					cpu {
						sound-dai = <0xffffffff>;
					};

					platform {
						sound-dai = <0xffffffff>;
					};
				};

				dual1 {

					cpu {
						sound-dai = <0xffffffff>;
					};

					platform {
						sound-dai = <0xffffffff>;
					};
				};

				dual2 {

					cpu {
						sound-dai = <0xffffffff>;
					};

					platform {
						sound-dai = <0xffffffff>;
					};
				};

				dual3 {

					cpu {
						sound-dai = <0xffffffff>;
					};

					platform {
						sound-dai = <0xffffffff>;
					};
				};

				dual4 {

					cpu {
						sound-dai = <0xffffffff>;
					};

					platform {
						sound-dai = <0xffffffff>;
					};
				};

				dual5 {

					cpu {
						sound-dai = <0xffffffff>;
					};

					platform {
						sound-dai = <0xffffffff>;
					};
				};

				dual6 {

					cpu {
						sound-dai = <0xffffffff>;
					};

					platform {
						sound-dai = <0xffffffff>;
					};
				};

				dual7 {

					cpu {
						sound-dai = <0xffffffff>;
					};

					platform {
						sound-dai = <0xffffffff>;
					};
				};

				dual8 {

					cpu {
						sound-dai = <0xffffffff>;
					};

					platform {
						sound-dai = <0xffffffff>;
					};
				};

				dual9 {

					cpu {
						sound-dai = <0xffffffff>;
					};

					platform {
						sound-dai = <0xffffffff>;
					};
				};

				dual10 {

					cpu {
						sound-dai = <0xffffffff>;
					};

					platform {
						sound-dai = <0xffffffff>;
					};
				};

				dual11 {

					cpu {
						sound-dai = <0xffffffff>;
					};

					platform {
						sound-dai = <0xffffffff>;
					};
				};

				ddma0 {

					cpu {
						sound-dai = <0xffffffff>;
					};

					platform {
						sound-dai = <0xffffffff>;
					};
				};

				ddma1 {

					cpu {
						sound-dai = <0xffffffff>;
					};

					platform {
						sound-dai = <0xffffffff>;
					};
				};

				ddma2 {

					cpu {
						sound-dai = <0xffffffff>;
					};

					platform {
						sound-dai = <0xffffffff>;
					};
				};

				ddma3 {

					cpu {
						sound-dai = <0xffffffff>;
					};

					platform {
						sound-dai = <0xffffffff>;
					};
				};

				ddma4 {

					cpu {
						sound-dai = <0xffffffff>;
					};

					platform {
						sound-dai = <0xffffffff>;
					};
				};

				ddma5 {

					cpu {
						sound-dai = <0xffffffff>;
					};

					platform {
						sound-dai = <0xffffffff>;
					};
				};

				uaif0 {
					format = "i2s";

					cpu {
						sound-dai = <0xffffffff>;
					};

					codec {
						sound-dai = <0x20>;
					};
				};

				uaif1 {
					format = "dsp_a";

					cpu {
						sound-dai = <0xffffffff>;
					};

					codec {
						sound-dai = <0x1e 0x00 0x1f 0x00>;
					};
				};

				uaif2 {
					format = "dsp_a";

					cpu {
						sound-dai = <0xffffffff>;
					};
				};

				uaif3 {
					format = "i2s";

					cpu {
						sound-dai = <0xffffffff>;
					};
				};

				uaif4 {
					format = "dsp_a";

					cpu {
						sound-dai = <0xffffffff>;
					};
				};

				uaif5 {
					format = "dsp_a";

					cpu {
						sound-dai = <0xffffffff>;
					};
				};

				uaif6 {
					format = "dsp_a";

					cpu {
						sound-dai = <0xffffffff>;
					};
				};

				dsif0 {
					format = "pdm";

					cpu {
						sound-dai = <0xffffffff>;
					};
				};

				spdy {

					cpu {
						sound-dai = <0xffffffff>;
					};
				};

				udma_rd0 {

					cpu {
						sound-dai = <0xffffffff>;
					};
				};

				udma_wr0 {

					cpu {
						sound-dai = <0xffffffff>;
					};
				};

				udma_wr_dual0 {

					cpu {
						sound-dai = <0xffffffff>;
					};
				};

				udma_wr_dbg0 {

					cpu {
						sound-dai = <0xffffffff>;
					};
				};

				rdma0_be {

					cpu {
						sound-dai = <0xffffffff 0x01>;
					};

					platform {
						sound-dai = <0xffffffff 0x01>;
					};
				};

				rdma1_be {

					cpu {
						sound-dai = <0xffffffff 0x01>;
					};

					platform {
						sound-dai = <0xffffffff 0x01>;
					};
				};

				rdma2_be {

					cpu {
						sound-dai = <0xffffffff 0x01>;
					};

					platform {
						sound-dai = <0xffffffff 0x01>;
					};
				};

				rdma3_be {

					cpu {
						sound-dai = <0xffffffff 0x01>;
					};

					platform {
						sound-dai = <0xffffffff 0x01>;
					};
				};

				rdma4_be {

					cpu {
						sound-dai = <0xffffffff 0x01>;
					};

					platform {
						sound-dai = <0xffffffff 0x01>;
					};
				};

				rdma5_be {

					cpu {
						sound-dai = <0xffffffff 0x01>;
					};

					platform {
						sound-dai = <0xffffffff 0x01>;
					};
				};

				rdma6_be {

					cpu {
						sound-dai = <0xffffffff 0x01>;
					};

					platform {
						sound-dai = <0xffffffff 0x01>;
					};
				};

				rdma7_be {

					cpu {
						sound-dai = <0xffffffff 0x01>;
					};

					platform {
						sound-dai = <0xffffffff 0x01>;
					};
				};

				rdma8_be {

					cpu {
						sound-dai = <0xffffffff 0x01>;
					};

					platform {
						sound-dai = <0xffffffff 0x01>;
					};
				};

				rdma9_be {

					cpu {
						sound-dai = <0xffffffff 0x01>;
					};

					platform {
						sound-dai = <0xffffffff 0x01>;
					};
				};

				rdma10_be {

					cpu {
						sound-dai = <0xffffffff 0x01>;
					};

					platform {
						sound-dai = <0xffffffff 0x01>;
					};
				};

				rdma11_be {

					cpu {
						sound-dai = <0xffffffff 0x01>;
					};

					platform {
						sound-dai = <0xffffffff 0x01>;
					};
				};

				wdma0_be {

					cpu {
						sound-dai = <0xffffffff 0x01>;
					};

					platform {
						sound-dai = <0xffffffff 0x01>;
					};
				};

				wdma1_be {

					cpu {
						sound-dai = <0xffffffff 0x01>;
					};

					platform {
						sound-dai = <0xffffffff 0x01>;
					};
				};

				wdma2_be {

					cpu {
						sound-dai = <0xffffffff 0x01>;
					};

					platform {
						sound-dai = <0xffffffff 0x01>;
					};
				};

				wdma3_be {

					cpu {
						sound-dai = <0xffffffff 0x01>;
					};

					platform {
						sound-dai = <0xffffffff 0x01>;
					};
				};

				wdma4_be {

					cpu {
						sound-dai = <0xffffffff 0x01>;
					};

					platform {
						sound-dai = <0xffffffff 0x01>;
					};
				};

				wdma5_be {

					cpu {
						sound-dai = <0xffffffff 0x01>;
					};

					platform {
						sound-dai = <0xffffffff 0x01>;
					};
				};

				wdma6_be {

					cpu {
						sound-dai = <0xffffffff 0x01>;
					};

					platform {
						sound-dai = <0xffffffff 0x01>;
					};
				};

				wdma7_be {

					cpu {
						sound-dai = <0xffffffff 0x01>;
					};

					platform {
						sound-dai = <0xffffffff 0x01>;
					};
				};

				wdma8_be {

					cpu {
						sound-dai = <0xffffffff 0x01>;
					};

					platform {
						sound-dai = <0xffffffff 0x01>;
					};
				};

				wdma9_be {

					cpu {
						sound-dai = <0xffffffff 0x01>;
					};

					platform {
						sound-dai = <0xffffffff 0x01>;
					};
				};

				wdma10_be {

					cpu {
						sound-dai = <0xffffffff 0x01>;
					};

					platform {
						sound-dai = <0xffffffff 0x01>;
					};
				};

				wdma11_be {

					cpu {
						sound-dai = <0xffffffff 0x01>;
					};

					platform {
						sound-dai = <0xffffffff 0x01>;
					};
				};

				usb {

					cpu {
						sound-dai = <0xffffffff 0x00>;
					};
				};

				fwd {

					cpu {
						sound-dai = <0xffffffff 0x01>;
					};
				};
			};
		};
	};

	fragment@17 {
		target = <0xffffffff>;

		__overlay__ {
			bootargs_ext = "panic_on_warn=1";
		};
	};

	fragment@18 {
		target = <0xffffffff>;

		__overlay__ {
			pinctrl-names;
		};
	};

	fragment@19 {
		target = <0xffffffff>;

		__overlay__ {
			pinctrl-names;
		};
	};

	fragment@20 {
		target = <0xffffffff>;

		__overlay__ {

			cs35l41-l-reset {
				samsung,pins = "gpp3-0";
				samsung,pin-function = <0x01>;
				samsung,pin-pud = <0x00>;
				samsung,pin-con-pdn = <0x03>;
				samsung,pin-pud-pdn = <0x00>;
				phandle = <0x24>;
			};

			cs35l41-l-int {
				samsung,pins = "gpp3-1";
				samsung,pin-function = <0x0f>;
				samsung,pin-pud = <0x00>;
				samsung,pin-con-pdn = <0x02>;
				samsung,pin-pud-pdn = <0x00>;
				phandle = <0x25>;
			};
		};
	};

	fragment@21 {
		target = <0xffffffff>;

		__overlay__ {

			cs35l41-r-reset {
				samsung,pins = "gpc9-0";
				samsung,pin-con-pdn = <0x03>;
				samsung,pin-pud-pdn = <0x00>;
				phandle = <0x21>;
			};

			cs35l41-r-int {
				samsung,pins = "gpc14-0";
				samsung,pin-pud = <0x00>;
				phandle = <0x22>;
			};
		};
	};

	fragment@22 {
		target = <0xffffffff>;

		__overlay__ {
			#address-cells = <0x01>;
			#size-cells = <0x00>;
			status = "okay";
			clock-frequency = <0x61a80>;

			cs35l41@40 {
				#sound-dai-cells = <0x01>;
				compatible = "cirrus,cs35l41";
				reg = <0x40>;
				interrupt-parent = <0xffffffff>;
				interrupts = <0x00 0x00 0x00>;
				pinctrl-names = "default";
				pinctrl-0 = <0x21 0x22>;
				reset-gpios = <0xffffffff 0x00 0x00>;
				VA-supply = <0x23>;
				VP-supply = <0x23>;
				cirrus,boost-peak-milliamp = <0x1194>;
				cirrus,boost-ind-nanohenry = <0x3e8>;
				cirrus,boost-cap-microfarad = <0x0f>;
				cirrus,dsp-noise-gate-enable;
				cirrus,dsp-noise-gate-delay = <0x02>;
				cirrus,dsp-noise-gate-threshold = <0x06>;
				cirrus,hw-noise-gate-select = <0x3f>;
				cirrus,hw-noise-gate-delay = <0x00>;
				cirrus,hw-noise-gate-threshold = <0x06>;
				cirrus,use-fsync-errata;
				cirrus,asp-sdout-hiz = <0x03>;
				cirrus,right-channel-amp;
				cirrus,mfd-suffix = "_r";
				phandle = <0x1f>;

				cirrus,gpio-config2 {
					cirrus,gpio-src-select = <0x04>;
					cirrus,gpio-output-enable;
				};
			};

			cs35l41@41 {
				#sound-dai-cells = <0x01>;
				compatible = "cirrus,cs35l41";
				reg = <0x41>;
				interrupt-parent = <0xffffffff>;
				interrupts = <0x01 0x00 0x00>;
				pinctrl-names = "default";
				pinctrl-0 = <0x24 0x25>;
				reset-gpios = <0xffffffff 0x00 0x00>;
				VA-supply = <0x23>;
				VP-supply = <0x23>;
				cirrus,boost-peak-milliamp = <0x1194>;
				cirrus,boost-ind-nanohenry = <0x3e8>;
				cirrus,boost-cap-microfarad = <0x0f>;
				cirrus,dsp-noise-gate-enable;
				cirrus,dsp-noise-gate-delay = <0x02>;
				cirrus,dsp-noise-gate-threshold = <0x06>;
				cirrus,hw-noise-gate-select = <0x3f>;
				cirrus,hw-noise-gate-delay = <0x00>;
				cirrus,hw-noise-gate-threshold = <0x06>;
				cirrus,use-fsync-errata;
				cirrus,asp-sdout-hiz = <0x03>;
				cirrus,mfd-suffix = [00];
				phandle = <0x1e>;

				cirrus,gpio-config2 {
					cirrus,gpio-src-select = <0x04>;
					cirrus,gpio-output-enable;
				};
			};
		};
	};

	fragment@23 {
		target = <0xffffffff>;

		__overlay__ {
			status = "okay";
		};
	};

	fragment@24 {
		target = <0xffffffff>;

		__overlay__ {
			status = "okay";
			lazy-vbus-up;

			dwc3 {
				dr_mode = "peripheral";
				maximum-speed = "high-speed";
			};
		};
	};

	fragment@25 {
		target = <0xffffffff>;

		__overlay__ {
			vcc-supply = <0x26>;
			vccq-supply = <0x27>;
		};
	};

	fragment@26 {
		target = <0xffffffff>;

		__overlay__ {
			status = "okay";
			maximum-speed = "high-speed";
			usb_audio_offloading = <0x01>;
			abox = <0xffffffff>;
			samsung,abox-gic = <0xffffffff>;
			xhci_l2_support = <0x01>;
			xhci_use_uram_for_audio = <0x01>;
			vdd33_usb-supply = <0x28>;
		};
	};

	fragment@27 {
		target = <0xffffffff>;

		__overlay__ {
			status = "okay";
			use_default_tune_val = <0x01>;
			low_power_call = <0x01>;
			hs_tune_param = <0x29>;
			vdd33_usb-supply = <0x28>;
		};
	};

	fragment@28 {
		target = <0xffffffff>;

		__overlay__ {

			key-volup {
				samsung,pins = "gpa1-0";
				samsung,pin-function = <0x0f>;
				samsung,pin-pud = <0x00>;
				samsung,pin-drv = <0x03>;
				phandle = <0x1b>;
			};

			key-voldown {
				samsung,pins = "gpa0-7";
				samsung,pin-function = <0x00>;
				samsung,pin-pud = <0x00>;
				samsung,pin-drv = <0x00>;
				phandle = <0x1c>;
			};

			attn-irq {
				samsung,pins = "gpa0-3";
				samsung,pin-function = <0x0f>;
				samsung,pin-pud = <0x03>;
				samsung,pin-drv = <0x03>;
				phandle = <0x2e>;
			};

			attn-input {
				samsung,pins = "gpa0-3";
				samsung,pin-function = <0x00>;
				samsung,pin-pud = <0x01>;
				phandle = <0x2f>;
			};

			dp-pmic-irq {
				samsung,pins = "gpa0-2";
				samsung,pin-function = <0x00>;
				samsung,pin-pud = <0x00>;
				samsung,pin-drv = <0x00>;
				phandle = <0x32>;
			};

			camera-pmic-irq {
				samsung,pins = "gpc11-0";
				samsung,pin-function = <0x00>;
				samsung,pin-pud = <0x00>;
				samsung,pin-drv = <0x00>;
				phandle = <0x36>;
			};

			if-pmic-irq {
				samsung,pins = "gpa0-4";
				samsung,pin-function = <0x00>;
				samsung,pin-pud = <0x00>;
				samsung,pin-drv = <0x00>;
				phandle = <0x33>;
			};

			usbpd-irq {
				samsung,pins = "gpa0-5";
				samsung,pin-function = <0x00>;
				samsung,pin-pud = <0x02>;
				samsung,pin-drv = <0x00>;
				phandle = <0x34>;
			};

			dc-irq {
				samsung,pins = "gpc3-0";
				samsung,pin-function = <0x0f>;
				samsung,pin-pud = <0x00>;
				samsung,pin-drv = <0x00>;
				phandle = <0x35>;
			};

			nfc-ven {
				samsung,pins = "gpc4-0";
				samsung,pin-function = <0x01>;
				samsung,pin-pud = <0x00>;
				samsung,pin-con-pdn = <0x03>;
				samsung,pin-pud-pdn = <0x00>;
				phandle = <0x2a>;
			};

			nfc-firm {
				samsung,pins = "gpc5-0";
				samsung,pin-function = <0x01>;
				samsung,pin-pud = <0x00>;
				samsung,pin-con-pdn = <0x03>;
				samsung,pin-pud-pdn = <0x00>;
				phandle = <0x2b>;
			};

			nfc-irq {
				samsung,pins = "gpa0-1";
				samsung,pin-function = <0x0f>;
				phandle = <0x2c>;
			};

			nfc-clkreq {
				samsung,pins = "gpa1-1";
				samsung,pin-function = <0x02>;
				samsung,pin-pud = <0x01>;
				phandle = <0x2d>;
			};
		};
	};

	fragment@29 {
		target = <0xffffffff>;

		__overlay__ {
			#address-cells = <0x01>;
			#size-cells = <0x00>;
			status = "okay";
			clock-frequency = <0x61a80>;

			sec-nfc@27 {
				compatible = "sec-nfc";
				reg = <0x27>;
				sec-nfc,ven-gpio = <0xffffffff 0x00 0x00>;
				sec-nfc,firm-gpio = <0xffffffff 0x00 0x00>;
				sec-nfc,irq-gpio = <0xffffffff 0x01 0x00>;
				sec-nfc,ldo_en = <0xffffffff 0x00 0x00>;
				sec-nfc,clk_req-gpio = <0xffffffff 0x01 0x00>;
				pinctrl-names = "default";
				pinctrl-0 = <0x2a 0x2b 0x2c 0x2d>;
			};
		};
	};

	fragment@30 {
		target = <0xffffffff>;

		__overlay__ {
			#address-cells = <0x01>;
			#size-cells = <0x00>;
			status = "okay";
			samsung,reset-before-trans;

			touchscreen@48 {
				compatible = "sec,sec_ts";
				reg = <0x48>;
				pinctrl-names = "on_state\0off_state";
				pinctrl-0 = <0x2e>;
				pinctrl-1 = <0x2f>;
				pressure-sensor = "Y";
				sec,irq_gpio = <0xffffffff 0x03 0x00>;
				sec,irq_type = <0x2008>;
				sec,max_coords = <0xfff 0xfff>;
				sec,mis_cal_check = <0x01>;
				dvdd-supply = <0x30>;
				avdd-supply = <0x31>;
				sec,always_lpmode = <0x01>;
				sec,project_name = "rice";
			};
		};
	};

	fragment@31 {
		target = <0xffffffff>;

		__overlay__ {
			#address-cells = <0x01>;
			#size-cells = <0x00>;
			status = "okay";

			s2dos05_pmic@60 {
				compatible = "samsung,s2dos05pmic";
				reg = <0x60>;
				s2dos05,wakeup;
				pinctrl-names = "default";
				pinctrl-0 = <0x32>;
				s2dos05,s2dos05_int = <0xffffffff 0x02 0x00>;
				adc_mode = <0x01>;
				adc_sync_mode = <0x02>;

				regulators {

					s2dos05-buck1 {
						regulator-name = "vdd1";
						regulator-min-microvolt = <0xcf850>;
						regulator-max-microvolt = <0x200b20>;
						regulator-initial-mode = <0x01>;
						phandle = <0x39>;
					};

					s2dos05-ldo1 {
						regulator-name = "vdd2";
						regulator-min-microvolt = <0x16e360>;
						regulator-max-microvolt = <0x1e8480>;
						regulator-initial-mode = <0x01>;
						phandle = <0x37>;
					};

					s2dos05-ldo2 {
						regulator-name = "vdd3";
						regulator-min-microvolt = <0x16e360>;
						regulator-max-microvolt = <0x1e8480>;
						regulator-initial-mode = <0x01>;
						phandle = <0x30>;
					};

					s2dos05-ldo3 {
						regulator-name = "vdd4";
						regulator-min-microvolt = <0x2932e0>;
						regulator-max-microvolt = <0x399a18>;
						regulator-initial-mode = <0x01>;
						phandle = <0x31>;
					};

					s2dos05-ldo4 {
						regulator-name = "vdd5";
						regulator-min-microvolt = <0x2932e0>;
						regulator-max-microvolt = <0x399a18>;
						regulator-initial-mode = <0x01>;
						phandle = <0x38>;
					};
				};
			};
		};
	};

	fragment@32 {
		target = <0xffffffff>;

		__overlay__ {
			#address-cells = <0x01>;
			#size-cells = <0x00>;
			status = "okay";

			s2mf301@3A {
				compatible = "samsung,s2mf301mfd";
				reg = <0x3a>;
				pinctrl-names = "default";
				pinctrl-0 = <0x33>;
				s2mf301,irq-gpio = <0xffffffff 0x04 0x00>;
				s2mf301,wakeup;
			};

			flash_led {
				status = "okay";
				default_current = <0x32>;
				max_current = <0xc8>;
				default_timer = <0x00>;

				s2mf301-channel1 {
					id = <0x00>;
				};
			};

			s2mf301-fuelgauge@3B {
				compatible = "samsung,s2mf301-fuelgauge";
				pinctrl-names = "default";
				fuelgauge,fuel_alert_vol = <0xd48>;
				fuelgauge,fuel_alert_soc = <0x01>;
				fuelgauge,type_str = "SDI";
				fuelgauge,model_type = <0x01>;
			};

			s2mf301-charger@3D {
				compatible = "samsung,s2mf301-charger";
				pinctrl-names = "default";
				battery,charger_name = "s2mf301-charger";
				battery,chg_gpio_en = <0x00>;
				battery,chg_polarity_en = <0x00>;
				battery,chg_gpio_status = <0x00>;
				battery,chg_polarity_status = <0x00>;
				battery,chg_float_voltage = <0x10fe>;
				battery,chg_recharge_vcell = <0x109a>;
				battery,chg_full_vcell = <0x10cc>;
				battery,full_check_type = <0x02>;
				battery,full_check_type_2nd = <0x02>;
				battery,input_current_limit = <0x1f4 0x1c2 0x1f4 0x4b0 0x1f4 0x4b0 0x4b0 0x3e8 0x3e8 0x3e8 0x3e8 0x1f4 0x1f4 0x4b0 0x3e8 0x1f4 0x1c2>;
				battery,fast_charging_current = <0x1f4 0x1c2 0x1f4 0x4b0 0x1f4 0x4b0 0x4b0 0x3e8 0x3e8 0x3e8 0x3e8 0x1f4 0x1f4 0x4b0 0x3e8 0x1f4 0x1c2>;
				battery,full_check_current_1st = <0x12c 0x00 0x12c 0x12c 0x12c 0x12c 0x12c 0x12c 0x12c 0x12c 0x12c 0x12c 0x12c 0x12c 0x12c 0x12c 0x00>;
				battery,full_check_current_2nd = <0x64 0x00 0x64 0x64 0x64 0x64 0x64 0x64 0x64 0x64 0x64 0x64 0x64 0x64 0x64 0x64 0x00>;
			};

			usbpd-s2mf301@3C {
				compatible = "sec-usbpd,i2c";
				reg = <0x3c>;
				pinctrl-names = "default";
				pinctrl-0 = <0x34>;
				usbpd,usbpd_int = <0xffffffff 0x05 0x00>;

				pdic-manager {
					pdic,max_power = <0x1388>;
					pdic_op_power = <0x9c4>;
					pdic_max_voltage = <0x1770>;
					pdic_max_current = <0x7d0>;
					pdic_min_current = <0x1f4>;
					pdic,giveback = <0x00>;
					pdic,usb_com_capable = <0x01>;
					pdic,no_usb_suspend = <0x01>;
					source,max_voltage = <0x1388>;
					source,min_voltage = <0xfa0>;
					source,max_power = <0x9c4>;
					sink,capable_max_voltage = <0x1388>;
				};
			};

			s2mc501-direct-charger@33 {
				compatible = "samsung,s2mc501-direct-charger";
				reg = <0x33>;
				pinctrl-names = "default";
				dc,direct_charger_name = "s2mc501-direct-charger";
				pinctrl-0 = <0x35>;
				s2mc501,irq-gpio = <0xffffffff 0x00 0x00>;
				s2mc501,enable-gpio = <0xffffffff 0x00 0x00>;
			};
		};
	};

	fragment@33 {
		target = <0xffffffff>;

		__overlay__ {
			#address-cells = <0x03>;
			#size-cells = <0x00>;
			status = "okay";

			s2mpb06_pmic@55 {
				compatible = "s2mpb06,s2mpb06mfd";
				reg = <0x55 0x00 0x10>;
				s2mpb06,wakeup;
				pinctrl-names = "default";
				pinctrl-0 = <0x36>;

				regulators {

					s2mpb06-ldo1 {
						regulator-name = "VDDD_1.05V_TELECAM";
						regulator-min-microvolt = <0x100590>;
						regulator-max-microvolt = <0x100590>;
						phandle = <0x65>;
					};

					s2mpb06-ldo2 {
						regulator-name = "VDDD_1.05V_UWCAM";
						regulator-min-microvolt = <0x100590>;
						regulator-max-microvolt = <0x100590>;
						phandle = <0x66>;
					};

					s2mpb06-ldo3 {
						regulator-name = "VDDA_2.8V_TELECAM";
						regulator-min-microvolt = <0x2ab980>;
						regulator-max-microvolt = <0x2ab980>;
						phandle = <0x67>;
					};

					s2mpb06-ldo4 {
						regulator-name = "VDDA_2.8V_UWCAM";
						regulator-min-microvolt = <0x2ab980>;
						regulator-max-microvolt = <0x2ab980>;
						phandle = <0x68>;
					};

					s2mpb06-ldo5 {
						regulator-name = "VDDIO_1.8V_CAMIO";
						regulator-min-microvolt = <0x1b7740>;
						regulator-max-microvolt = <0x1b7740>;
						phandle = <0x69>;
					};

					s2mpb06-ldo6 {
						regulator-name = "VDDOIS_2.8V_TELECAM";
						regulator-min-microvolt = <0x2ab980>;
						regulator-max-microvolt = <0x2ab980>;
						phandle = <0x6a>;
					};

					s2mpb06-ldo7 {
						regulator-name = "VDDAF_2.8V_TELECAM";
						regulator-min-microvolt = <0x2ab980>;
						regulator-max-microvolt = <0x2ab980>;
						phandle = <0x6b>;
					};
				};
			};
		};
	};

	fragment@34 {
		target = <0xffffffff>;

		__overlay__ {
			#address-cells = <0x01>;
			#size-cells = <0x00>;

			drmpanel {
				compatible = "samsung,command-ctrl";
				reset-gpios = <0xffffffff 0x00 0x00>;
				vddi-supply = <0x37>;
				vci-supply = <0x38>;
				vddr-supply = <0x39>;
				reg = <0x00>;
			};
		};
	};

	fragment@35 {
		target = <0xffffffff>;

		__overlay__ {
			elna_gpio = <0xffffffff 0x00 0x01>;
		};
	};

	fragment@36 {
		target = <0xffffffff>;

		__overlay__ {

			drmpanel {

				samsung_emulation_video_panel {
					samsung,panel-name = "samsung emulation panel";
					phandle = <0x6c>;

					display-timings {

						1080x2400@60 {
							exynos,mode-type = <0x48>;
							exynos,refresh-rate = <0x3c>;
							exynos,hactive = <0x438>;
							exynos,hfront-porch = <0x14>;
							exynos,hsync-len = <0x02>;
							exynos,hback-porch = <0x14>;
							exynos,vactive = <0x960>;
							exynos,vfront-porch = <0x14>;
							exynos,vsync-len = <0x02>;
							exynos,vback-porch = <0x14>;
							exynos,mode-flags = <0x00>;
							exynos,bpc = <0x08>;
							exynos,lp-mode = <0x00>;
							exynos,dsc-en = <0x00>;
							exynos,on-cmds = <0x01 0x11 0x00 0x01 0x29 0x00>;
							exynos,off-cmds = <0x01 0x10 0x00 0x01 0x28 0x00>;
						};
					};
				};
			};
		};
	};

	fragment@37 {
		target = <0xffffffff>;

		__overlay__ {

			drmpanel {

				s6e3hab_1080_2400_120_cmd {
					samsung,panel-name = "samsung s6e3hab 1080x2400 120Hz command mode panel";
					samsung,max-brightness = <0x3ff>;
					samsung,default-brightness = <0x1ff>;
					samsung,doze-supported;
					samsung,reset-sequence = <0x01 0x00 0x01>;
					samsung,reset-udelay = <0x00 0x1388 0x1388 0x2710>;
					samsung,lcd-size-mm = <0x4b 0xa5>;
					phandle = <0x6d>;

					display-timings {

						1080x2400@60 {
							exynos,mode-type = <0x48>;
							exynos,refresh-rate = <0x3c>;
							exynos,hactive = <0x438>;
							exynos,hfront-porch = <0x02>;
							exynos,hsync-len = <0x02>;
							exynos,hback-porch = <0x02>;
							exynos,vactive = <0x960>;
							exynos,vfront-porch = <0x08>;
							exynos,vsync-len = <0x01>;
							exynos,vback-porch = <0x0f>;
							exynos,clock-frequency = <0x268fc>;
							exynos,mode-flags = <0x0a>;
							exynos,bpc = <0x08>;
							exynos,lp-mode = <0x00>;
							exynos,dsc-en = <0x01>;
							exynos,dsc-count = <0x01>;
							exynos,dsc-slice-count = <0x02>;
							exynos,dsc-slice-height = <0x28>;
							exynos,pre-pps-cmds = <0x03 0x9f 0xa5 0xa5 0x00>;
							exynos,pps-cmds = <0x80 0x11 0x00 0x00 0x89 0x30 0x80 0x09 0x60 0x04 0x38 0x00 0x28 0x02 0x1c 0x02 0x1c 0x02 0x00 0x02 0x0e 0x00 0x20 0x03 0xdd 0x00 0x07 0x00 0x0c 0x02 0x77 0x02 0x8b 0x18 0x00 0x10 0xf0 0x03 0x0c 0x20 0x00 0x06 0x0b 0x0b 0x33 0x0e 0x1c 0x2a 0x38 0x46 0x54 0x62 0x69 0x70 0x77 0x79 0x7b 0x7d 0x7e 0x01 0x02 0x01 0x00 0x09 0x40 0x09 0xbe 0x19 0xfc 0x19 0xfa 0x19 0xf8 0x1a 0x38 0x1a 0x78 0x1a 0xb6 0x2a 0xf6 0x2b 0x34 0x2b 0x74 0x3b 0x74 0x6b 0xf4 0x00 0x00 0x00 0x00 0x00 0x00 0x00 0x00 0x00 0x00 0x00 0x00 0x00 0x00 0x00 0x00 0x00 0x00 0x00 0x00 0x00 0x00 0x00 0x00 0x00 0x00 0x00 0x00 0x00 0x00 0x00 0x00 0x00 0x00 0x00 0x00 0x00 0x00 0x00 0x00 0x00>;
							exynos,post-pps-cmds = <0x03 0x9f 0x5a 0x5a 0x00>;
							exynos,on-cmds = <0x03 0xf0 0x5a 0x5a 0x00 0x03 0xfc 0x5a 0x5a 0x00 0x01 0x11 0xc8 0x0a 0xb9 0x00 0xc0 0x8c 0x09 0x00 0x00 0x00 0x11 0x03 0x00 0x02 0x53 0x20 0x00 0x03 0x51 0xff 0x7f 0x00 0x01 0x35 0x00 0x03 0xed 0x04 0x44 0x00 0x05 0xb9 0x00 0xc0 0x8c 0x09 0x00>;
							exynos,tectrl-cmds = <0x03 0xf0 0x5a 0x5a 0x00 0x05 0xb9 0x01 0xb0 0xc4 0x09 0x00 0x03 0xf0 0xa5 0xa5 0x00>;
							exynos,vref-cmds = <0x03 0xf0 0x5a 0x5a 0x00 0x03 0x9f 0xa5 0xa5 0x00 0x02 0x60 0x00 0x00 0x03 0x9f 0x5a 0x5a 0x00 0x02 0xf7 0x0f 0x00 0x03 0xf0 0xa5 0xa5 0x00>;
							exynos,mres-cmds = <0x05 0x2a 0x00 0x00 0x04 0x37 0x00 0x05 0x2b 0x00 0x00 0x09 0x5f 0x00 0x03 0xf0 0x5a 0x5a 0x00 0x02 0xba 0x02 0x00 0x03 0xf0 0xa5 0xa5 0x00>;
							exynos,disp-on-cmds = <0x03 0x9f 0xa5 0xa5 0x00 0x01 0x29 0x00 0x03 0x9f 0x5a 0x5a 0x00>;
							exynos,off-cmds = <0x01 0x10 0x00 0x01 0x28 0x00>;
						};

						1080x2400@120 {
							exynos,mode-type = <0x40>;
							exynos,refresh-rate = <0x78>;
							exynos,hactive = <0x438>;
							exynos,hfront-porch = <0x02>;
							exynos,hsync-len = <0x02>;
							exynos,hback-porch = <0x02>;
							exynos,vactive = <0x960>;
							exynos,vfront-porch = <0x08>;
							exynos,vsync-len = <0x01>;
							exynos,vback-porch = <0x0f>;
							exynos,clock-frequency = <0x4d1f6>;
							exynos,mode-flags = <0x0a>;
							exynos,bpc = <0x08>;
							exynos,lp-mode = <0x00>;
							exynos,dsc-en = <0x01>;
							exynos,dsc-count = <0x01>;
							exynos,dsc-slice-count = <0x02>;
							exynos,dsc-slice-height = <0x28>;
							exynos,pre-pps-cmds = <0x03 0x9f 0xa5 0xa5 0x00>;
							exynos,pps-cmds = <0x80 0x11 0x00 0x00 0x89 0x30 0x80 0x09 0x60 0x04 0x38 0x00 0x28 0x02 0x1c 0x02 0x1c 0x02 0x00 0x02 0x0e 0x00 0x20 0x03 0xdd 0x00 0x07 0x00 0x0c 0x02 0x77 0x02 0x8b 0x18 0x00 0x10 0xf0 0x03 0x0c 0x20 0x00 0x06 0x0b 0x0b 0x33 0x0e 0x1c 0x2a 0x38 0x46 0x54 0x62 0x69 0x70 0x77 0x79 0x7b 0x7d 0x7e 0x01 0x02 0x01 0x00 0x09 0x40 0x09 0xbe 0x19 0xfc 0x19 0xfa 0x19 0xf8 0x1a 0x38 0x1a 0x78 0x1a 0xb6 0x2a 0xf6 0x2b 0x34 0x2b 0x74 0x3b 0x74 0x6b 0xf4 0x00 0x00 0x00 0x00 0x00 0x00 0x00 0x00 0x00 0x00 0x00 0x00 0x00 0x00 0x00 0x00 0x00 0x00 0x00 0x00 0x00 0x00 0x00 0x00 0x00 0x00 0x00 0x00 0x00 0x00 0x00 0x00 0x00 0x00 0x00 0x00 0x00 0x00 0x00 0x00 0x00>;
							exynos,post-pps-cmds = <0x03 0x9f 0x5a 0x5a 0x00>;
							exynos,on-cmds = <0x03 0xf0 0x5a 0x5a 0x00 0x03 0xfc 0x5a 0x5a 0x00 0x01 0x11 0xc8 0x0a 0xb9 0x00 0xc0 0x8c 0x09 0x00 0x00 0x00 0x11 0x03 0x00 0x02 0x53 0x20 0x00 0x03 0x51 0xff 0x7f 0x00 0x01 0x35 0x00 0x03 0xed 0x04 0x44 0x00 0x05 0xb9 0x00 0xc0 0x8c 0x09 0x00>;
							exynos,tectrl-cmds = <0x03 0xf0 0x5a 0x5a 0x00 0x05 0xb9 0x01 0xa0 0xfc 0x09 0x00 0x03 0xf0 0xa5 0xa5 0x00>;
							exynos,vref-cmds = <0x03 0xf0 0x5a 0x5a 0x00 0x03 0x9f 0xa5 0xa5 0x00 0x02 0x60 0x20 0x00 0x03 0x9f 0x5a 0x5a 0x00 0x02 0xf7 0x0f 0x00 0x03 0xf0 0xa5 0xa5 0x00>;
							exynos,mres-cmds = <0x05 0x2a 0x00 0x00 0x04 0x37 0x00 0x05 0x2b 0x00 0x00 0x09 0x5f 0x00 0x03 0xf0 0x5a 0x5a 0x00 0x02 0xba 0x02 0x00 0x03 0xf0 0xa5 0xa5 0x00>;
							exynos,disp-on-cmds = <0x03 0x9f 0xa5 0xa5 0x00 0x01 0x29 0x00 0x03 0x9f 0x5a 0x5a 0x00>;
							exynos,off-cmds = <0x01 0x10 0x00 0x01 0x28 0x00>;
						};

						1080x2400@30 {
							exynos,mode-type = <0x40>;
							exynos,refresh-rate = <0x1e>;
							exynos,hactive = <0x438>;
							exynos,hfront-porch = <0x02>;
							exynos,hsync-len = <0x02>;
							exynos,hback-porch = <0x02>;
							exynos,vactive = <0x960>;
							exynos,vfront-porch = <0x08>;
							exynos,vsync-len = <0x01>;
							exynos,vback-porch = <0x0f>;
							exynos,clock-frequency = <0x1347e>;
							exynos,mode-flags = <0x0a>;
							exynos,bpc = <0x08>;
							exynos,lp-mode = <0x01>;
							exynos,dsc-en = <0x01>;
							exynos,dsc-count = <0x01>;
							exynos,dsc-slice-count = <0x02>;
							exynos,dsc-slice-height = <0x28>;
							exynos,pps-cmds = <0x80 0x11 0x00 0x00 0x89 0x30 0x80 0x09 0x60 0x04 0x38 0x00 0x28 0x02 0x1c 0x02 0x1c 0x02 0x00 0x02 0x0e 0x00 0x20 0x03 0xdd 0x00 0x07 0x00 0x0c 0x02 0x77 0x02 0x8b 0x18 0x00 0x10 0xf0 0x03 0x0c 0x20 0x00 0x06 0x0b 0x0b 0x33 0x0e 0x1c 0x2a 0x38 0x46 0x54 0x62 0x69 0x70 0x77 0x79 0x7b 0x7d 0x7e 0x01 0x02 0x01 0x00 0x09 0x40 0x09 0xbe 0x19 0xfc 0x19 0xfa 0x19 0xf8 0x1a 0x38 0x1a 0x78 0x1a 0xb6 0x2a 0xf6 0x2b 0x34 0x2b 0x74 0x3b 0x74 0x6b 0xf4 0x00 0x00 0x00 0x00 0x00 0x00 0x00 0x00 0x00 0x00 0x00 0x00 0x00 0x00 0x00 0x00 0x00 0x00 0x00 0x00 0x00 0x00 0x00 0x00 0x00 0x00 0x00 0x00 0x00 0x00 0x00 0x00 0x00 0x00 0x00 0x00 0x00 0x00 0x00 0x00 0x00>;
						};
					};
				};
			};
		};
	};

	fragment@38 {
		target = <0xffffffff>;

		__overlay__ {

			drmpanel {

				s6e8fc1_720_1600_vid {
					samsung,panel-name = "samsung s6e8fc1 720x1600 video mode panel";
					samsung,max-brightness = <0x3ff>;
					samsung,default-brightness = <0x1ff>;
					samsung,reset-sequence = <0x01 0x00 0x01>;
					samsung,reset-udelay = <0x2710 0x1388 0x1388 0x2710>;
					samsung,reset-position = <0x00>;
					samsung,lcd-size-mm = <0x4b 0xa5>;
					phandle = <0x6e>;

					display-timings {

						720x1600@60 {
							exynos,mode-type = <0x48>;
							exynos,refresh-rate = <0x3c>;
							exynos,hactive = <0x2d0>;
							exynos,hfront-porch = <0x1a>;
							exynos,hsync-len = <0x04>;
							exynos,hback-porch = <0x30>;
							exynos,vactive = <0x640>;
							exynos,vfront-porch = <0x05>;
							exynos,vsync-len = <0x02>;
							exynos,vback-porch = <0x09>;
							exynos,clock-frequency = <0x12e3f>;
							exynos,mode-flags = <0x00>;
							exynos,bpc = <0x08>;
							exynos,lp-mode = <0x00>;
							exynos,dsc-en = <0x00>;
							exynos,on-cmds = <0x01 0x11 0x14 0x03 0xf0 0x5a 0x5a 0x00 0x03 0xfc 0x5a 0x5a 0x00 0x0e 0xed 0x00 0x01 0x00 0x40 0x04 0x08 0xa8 0x84 0x4a 0x73 0x02 0x0a 0x00 0x00 0x03 0xf1 0xa5 0xa5 0x00 0x02 0x53 0x20 0x00 0x07 0xb3 0x11 0x50 0xdd 0x0d 0xc0 0x0a 0x00 0x03 0x51 0x03 0xff 0x00 0x02 0xf9 0x20 0x00 0x03 0xf0 0xa5 0xa5 0x64>;
							exynos,disp-on-cmds = <0x01 0x29 0x00>;
							exynos,off-cmds = <0x01 0x10 0x00 0x01 0x28 0x00>;
						};

						720x1600@40 {
							exynos,mode-type = <0x40>;
							exynos,refresh-rate = <0x28>;
							exynos,hactive = <0x2d0>;
							exynos,hfront-porch = <0x1a>;
							exynos,hsync-len = <0x04>;
							exynos,hback-porch = <0x30>;
							exynos,vactive = <0x640>;
							exynos,vfront-porch = <0x32a>;
							exynos,vsync-len = <0x02>;
							exynos,vback-porch = <0x09>;
							exynos,clock-frequency = <0x12e3f>;
							exynos,mode-flags = <0x00>;
							exynos,bpc = <0x08>;
							exynos,lp-mode = <0x00>;
							exynos,dsc-en = <0x00>;
							exynos,on-cmds = <0x01 0x11 0x14 0x03 0xf0 0x5a 0x5a 0x00 0x03 0xfc 0x5a 0x5a 0x00 0x0e 0xed 0x00 0x01 0x00 0x40 0x04 0x08 0xa8 0x84 0x4a 0x73 0x02 0x0a 0x00 0x00 0x03 0xf1 0xa5 0xa5 0x00 0x02 0x53 0x20 0x00 0x07 0xb3 0x11 0x50 0xdd 0x0d 0xc0 0x0a 0x00 0x03 0x51 0x03 0xff 0x00 0x02 0xf9 0x20 0x00 0x03 0xf0 0xa5 0xa5 0x64>;
							exynos,disp-on-cmds = <0x01 0x29 0x00>;
							exynos,off-cmds = <0x01 0x10 0x00 0x01 0x28 0x00>;
						};
					};
				};
			};
		};
	};

	fragment@39 {
		target = <0xffffffff>;

		__overlay__ {

			drmpanel {
				default-panel = "s6e3hab_1080_2400_120_cmd";
			};
		};
	};

	__symbols__ {
		tray_detect = "/fragment@0/__overlay__/tray_detect";
		is_sensor_3h1 = "/fragment@camera/__overlay__/is_sensor_3h1@31";
		is_sensor_2la = "/fragment@camera/__overlay__/is_sensor_2la@2D";
		is_sensor_gw2 = "/fragment@camera/__overlay__/is_sensor_gw2@5A";
		is_flash_s2mf301 = "/fragment@camera/__overlay__/is-flash-s2mf301@0";
		is_flash_s2mf301_2 = "/fragment@camera/__overlay__/is-flash-s2mf301_2@0";
		is_sensor0 = "/fragment@camera/__overlay__/is_sensor0@15030000";
		is_sensor1 = "/fragment@camera/__overlay__/is_sensor1@15040000";
		is_sensor2 = "/fragment@camera/__overlay__/is_sensor2@15050000";
		is_sensor3 = "/fragment@camera/__overlay__/is_sensor3@15060000";
		hsi2c23_bus = "/fragment@1/__overlay__/hsi2c23-bus";
		hsi2c23_bus_in = "/fragment@1/__overlay__/hsi2c23-bus-in";
		hsi2c29_bus = "/fragment@1/__overlay__/hsi2c29-bus";
		hsi2c29_bus_in = "/fragment@1/__overlay__/hsi2c29-bus-in";
		hsi2c28_bus = "/fragment@1/__overlay__/hsi2c28-bus";
		hsi2c28_bus_in = "/fragment@1/__overlay__/hsi2c28-bus-in";
		hsi2c25_bus = "/fragment@1/__overlay__/hsi2c25-bus";
		hsi2c25_bus_in = "/fragment@1/__overlay__/hsi2c25-bus-n";
		hsi2c20_bus = "/fragment@1/__overlay__/hsi2c20-bus";
		hsi2c20_bus_in = "/fragment@1/__overlay__/hsi2c20-bus-in";
		hsi2c21_bus = "/fragment@1/__overlay__/hsi2c21-bus";
		hsi2c21_bus_in = "/fragment@1/__overlay__/hsi2c21-bus-in";
		but_zones = "/fragment@9/__overlay__/but_zones";
		imp_range = "/fragment@9/__overlay__/imp_range";
		mic_range = "/fragment@9/__overlay__/mic_range";
		wtp_range = "/fragment@9/__overlay__/wtp_range";
		s5m3700x_irq = "/fragment@10/__overlay__/s5m3700x-irq";
		s5m3700x_external_ldo_1_8v = "/fragment@10/__overlay__/s5m3700x_external_ldo_1_8v";
		s5m3700x_resetb = "/fragment@11/__overlay__/s5m3700x_resetb";
		s5m3700x_external_ldo_3_4v = "/fragment@11/__overlay__/s5m3700x_external_ldo_3_4v";
		codec_s5m3700x = "/fragment@12/__overlay__/s5m3700x@14";
		pm_wrstbi = "/fragment@13/__overlay__/pm-wrstbi";
		smpl_warn = "/fragment@14/__overlay__/smpl-warn";
		s2mpu15_gpadc = "/fragment@15/__overlay__/s2mpu15mfd@1f/s2mpu15-gpadc";
		s2mpu15_gpio = "/fragment@15/__overlay__/s2mpu15mfd@1f/s2mpu15-gpio";
		b1_reg = "/fragment@15/__overlay__/s2mpu15mfd@1f/regulators/BUCK1";
		b2_reg = "/fragment@15/__overlay__/s2mpu15mfd@1f/regulators/BUCK2";
		b3_reg = "/fragment@15/__overlay__/s2mpu15mfd@1f/regulators/BUCK3";
		b4_reg = "/fragment@15/__overlay__/s2mpu15mfd@1f/regulators/BUCK4";
		b5_reg = "/fragment@15/__overlay__/s2mpu15mfd@1f/regulators/BUCK5";
		b6_reg = "/fragment@15/__overlay__/s2mpu15mfd@1f/regulators/BUCK6";
		b7_reg = "/fragment@15/__overlay__/s2mpu15mfd@1f/regulators/BUCK7";
		b8_reg = "/fragment@15/__overlay__/s2mpu15mfd@1f/regulators/BUCK8";
		b_sr1_reg = "/fragment@15/__overlay__/s2mpu15mfd@1f/regulators/BUCK_SR1";
		b_sr2_reg = "/fragment@15/__overlay__/s2mpu15mfd@1f/regulators/BUCK_SR2";
		b_sr3_reg = "/fragment@15/__overlay__/s2mpu15mfd@1f/regulators/BUCK_SR3";
		b_sr4_reg = "/fragment@15/__overlay__/s2mpu15mfd@1f/regulators/BUCK_SR4";
		l1_reg = "/fragment@15/__overlay__/s2mpu15mfd@1f/regulators/LDO1";
		l2_reg = "/fragment@15/__overlay__/s2mpu15mfd@1f/regulators/LDO2";
		l3_reg = "/fragment@15/__overlay__/s2mpu15mfd@1f/regulators/LDO3";
		l4_reg = "/fragment@15/__overlay__/s2mpu15mfd@1f/regulators/LDO4";
		l5_reg = "/fragment@15/__overlay__/s2mpu15mfd@1f/regulators/LDO5";
		l6_reg = "/fragment@15/__overlay__/s2mpu15mfd@1f/regulators/LDO6";
		l7_reg = "/fragment@15/__overlay__/s2mpu15mfd@1f/regulators/LDO7";
		l16_reg = "/fragment@15/__overlay__/s2mpu15mfd@1f/regulators/LDO16";
		l17_reg = "/fragment@15/__overlay__/s2mpu15mfd@1f/regulators/LDO17";
		l18_reg = "/fragment@15/__overlay__/s2mpu15mfd@1f/regulators/LDO18";
		l19_reg = "/fragment@15/__overlay__/s2mpu15mfd@1f/regulators/LDO19";
		l25_reg = "/fragment@15/__overlay__/s2mpu15mfd@1f/regulators/LDO25";
		l28_reg = "/fragment@15/__overlay__/s2mpu15mfd@1f/regulators/LDO28";
		l29_reg = "/fragment@15/__overlay__/s2mpu15mfd@1f/regulators/LDO29";
		l30_reg = "/fragment@15/__overlay__/s2mpu15mfd@1f/regulators/LDO30";
		l31_reg = "/fragment@15/__overlay__/s2mpu15mfd@1f/regulators/LDO31";
		l32_reg = "/fragment@15/__overlay__/s2mpu15mfd@1f/regulators/LDO32";
		l33_reg = "/fragment@15/__overlay__/s2mpu15mfd@1f/regulators/LDO33";
		l34_reg = "/fragment@15/__overlay__/s2mpu15mfd@1f/regulators/LDO34";
		l35_reg = "/fragment@15/__overlay__/s2mpu15mfd@1f/regulators/LDO35";
		s2mpa05_gpio = "/fragment@16/__overlay__/s2mpa05mfd@2f/s2mpa05-gpio";
		s_b3_reg = "/fragment@16/__overlay__/s2mpa05mfd@2f/regulators/BUCK3";
		s_l2_reg = "/fragment@16/__overlay__/s2mpa05mfd@2f/regulators/LDO2";
		s_l3_reg = "/fragment@16/__overlay__/s2mpa05mfd@2f/regulators/LDO3";
		usb_hs_tune = "/fragment@model/__overlay__/hs_tune";
		gnss_mailbox = "/fragment@model/__overlay__/gnss_mailbox";
		vbat = "/fragment@model/__overlay__/vbat";
		dummy_audio_codec = "/fragment@model/__overlay__/audio-codec-dummy";
		dummy_audio_cpu = "/fragment@model/__overlay__/audio-cpu-dummy";
		cs35l41_l_reset = "/fragment@20/__overlay__/cs35l41-l-reset";
		cs35l41_l_int = "/fragment@20/__overlay__/cs35l41-l-int";
		cs35l41_r_reset = "/fragment@21/__overlay__/cs35l41-r-reset";
		cs35l41_r_int = "/fragment@21/__overlay__/cs35l41-r-int";
		cs35l41_r = "/fragment@22/__overlay__/cs35l41@40";
		cs35l41_l = "/fragment@22/__overlay__/cs35l41@41";
		key_volup = "/fragment@28/__overlay__/key-volup";
		key_voldown = "/fragment@28/__overlay__/key-voldown";
		attn_irq = "/fragment@28/__overlay__/attn-irq";
		attn_input = "/fragment@28/__overlay__/attn-input";
		dp_pmic_irq = "/fragment@28/__overlay__/dp-pmic-irq";
		camera_pmic_irq = "/fragment@28/__overlay__/camera-pmic-irq";
		if_pmic_irq = "/fragment@28/__overlay__/if-pmic-irq";
		usbpd_irq = "/fragment@28/__overlay__/usbpd-irq";
		dc_irq = "/fragment@28/__overlay__/dc-irq";
		nfc_ven = "/fragment@28/__overlay__/nfc-ven";
		nfc_firm = "/fragment@28/__overlay__/nfc-firm";
		nfc_irq = "/fragment@28/__overlay__/nfc-irq";
		nfc_clkreq = "/fragment@28/__overlay__/nfc-clkreq";
		dp_buck = "/fragment@31/__overlay__/s2dos05_pmic@60/regulators/s2dos05-buck1";
		dp_ldo1 = "/fragment@31/__overlay__/s2dos05_pmic@60/regulators/s2dos05-ldo1";
		dp_ldo2 = "/fragment@31/__overlay__/s2dos05_pmic@60/regulators/s2dos05-ldo2";
		dp_ldo3 = "/fragment@31/__overlay__/s2dos05_pmic@60/regulators/s2dos05-ldo3";
		dp_ldo4 = "/fragment@31/__overlay__/s2dos05_pmic@60/regulators/s2dos05-ldo4";
		_ldo1_reg = "/fragment@33/__overlay__/s2mpb06_pmic@55/regulators/s2mpb06-ldo1";
		_ldo2_reg = "/fragment@33/__overlay__/s2mpb06_pmic@55/regulators/s2mpb06-ldo2";
		_ldo3_reg = "/fragment@33/__overlay__/s2mpb06_pmic@55/regulators/s2mpb06-ldo3";
		_ldo4_reg = "/fragment@33/__overlay__/s2mpb06_pmic@55/regulators/s2mpb06-ldo4";
		_ldo5_reg = "/fragment@33/__overlay__/s2mpb06_pmic@55/regulators/s2mpb06-ldo5";
		_ldo6_reg = "/fragment@33/__overlay__/s2mpb06_pmic@55/regulators/s2mpb06-ldo6";
		_ldo7_reg = "/fragment@33/__overlay__/s2mpb06_pmic@55/regulators/s2mpb06-ldo7";
		samsung_emulation_video_panel = "/fragment@36/__overlay__/drmpanel/samsung_emulation_video_panel";
		s6e3hab_1080_2400_120_cmd = "/fragment@37/__overlay__/drmpanel/s6e3hab_1080_2400_120_cmd";
		s6e8fc1_720_1600_vid = "/fragment@38/__overlay__/drmpanel/s6e8fc1_720_1600_vid";
	};

	__fixups__ {
		gic = "/fragment@modemif/__overlay__/cpif:interrupt-parent:0\0/fragment@modemif/__overlay__/cp_mailbox:interrupt-parent:0\0/fragment@dit/__overlay__/dit:interrupt-parent:0\0/fragment@camera/__overlay__:interrupt-parent:0\0/fragment@15/__overlay__/s2mpu15mfd@1f:interrupt-parent:0\0/fragment@model/__overlay__/gnss_mailbox:interrupt-parent:0\0/fragment@model/__overlay__/gnssif:interrupt-parent:0";
		cp_rmem = "/fragment@modemif/__overlay__/cp_shmem:memory-region:0";
		cp_rmem1 = "/fragment@modemif/__overlay__/cp_shmem:memory-region:4";
		pinctrl_0 = "/fragment@0:target:0\0/fragment@10:target:0\0/fragment@13:target:0\0/fragment@21:target:0\0/fragment@28:target:0";
		sensor_mclk2_out = "/fragment@camera/__overlay__/is_sensor_3h1@31:pinctrl-1:0";
		sensor_mclk2_fn = "/fragment@camera/__overlay__/is_sensor_3h1@31:pinctrl-2:0";
		gpg0 = "/fragment@camera/__overlay__/is_sensor_3h1@31/power_seq:gpio_mclk:0\0/fragment@camera/__overlay__/is_sensor_2la@2D/power_seq:gpio_mclk:0\0/fragment@camera/__overlay__/is_sensor_gw2@5A/power_seq:gpio_mclk:0\0/fragment@15/__overlay__/s2mpu15mfd@1f:gpios:0";
		gpm9 = "/fragment@camera/__overlay__/is_sensor_3h1@31/power_seq/scenario_normal_on/10:gpio:0\0/fragment@camera/__overlay__/is_sensor_3h1@31/power_seq/scenario_normal_on/70:gpio:0\0/fragment@camera/__overlay__/is_sensor_3h1@31/power_seq/scenario_vision_on/10:gpio:0\0/fragment@camera/__overlay__/is_sensor_3h1@31/power_seq/scenario_vision_on/70:gpio:0\0/fragment@camera/__overlay__/is_sensor_3h1@31/power_seq/scenario_normal_off/50:gpio:0\0/fragment@camera/__overlay__/is_sensor_3h1@31/power_seq/scenario_vision_off/50:gpio:0";
		gpp0 = "/fragment@camera/__overlay__/is_sensor_3h1@31/power_seq/scenario_normal_on/30:gpio:0\0/fragment@camera/__overlay__/is_sensor_3h1@31/power_seq/scenario_normal_on/50:gpio:0\0/fragment@camera/__overlay__/is_sensor_3h1@31/power_seq/scenario_vision_on/30:gpio:0\0/fragment@camera/__overlay__/is_sensor_3h1@31/power_seq/scenario_vision_on/50:gpio:0\0/fragment@camera/__overlay__/is_sensor_3h1@31/power_seq/scenario_normal_off/70:gpio:0\0/fragment@camera/__overlay__/is_sensor_3h1@31/power_seq/scenario_normal_off/90:gpio:0\0/fragment@camera/__overlay__/is_sensor_3h1@31/power_seq/scenario_vision_off/70:gpio:0\0/fragment@camera/__overlay__/is_sensor_3h1@31/power_seq/scenario_vision_off/90:gpio:0";
		gpp1 = "/fragment@camera/__overlay__/is_sensor_3h1@31/power_seq/scenario_normal_on/40:gpio:0\0/fragment@camera/__overlay__/is_sensor_3h1@31/power_seq/scenario_vision_on/40:gpio:0\0/fragment@camera/__overlay__/is_sensor_3h1@31/power_seq/scenario_normal_off/80:gpio:0\0/fragment@camera/__overlay__/is_sensor_3h1@31/power_seq/scenario_vision_off/80:gpio:0";
		sensor_mclk1_out = "/fragment@camera/__overlay__/is_sensor_2la@2D:pinctrl-1:0";
		sensor_mclk1_fn = "/fragment@camera/__overlay__/is_sensor_2la@2D:pinctrl-2:0";
		gpm8 = "/fragment@camera/__overlay__/is_sensor_2la@2D/power_seq/scenario_normal_on/10:gpio:0\0/fragment@camera/__overlay__/is_sensor_2la@2D/power_seq/scenario_normal_on/60:gpio:0\0/fragment@camera/__overlay__/is_sensor_2la@2D/power_seq/scenario_normal_off/10:gpio:0\0/fragment@camera/__overlay__/is_sensor_2la@2D/power_seq/scenario_vision_on/10:gpio:0\0/fragment@camera/__overlay__/is_sensor_2la@2D/power_seq/scenario_vision_on/60:gpio:0\0/fragment@camera/__overlay__/is_sensor_2la@2D/power_seq/scenario_vision_off/10:gpio:0";
		sensor_mclk0_out = "/fragment@camera/__overlay__/is_sensor_gw2@5A:pinctrl-1:0";
		sensor_mclk0_fn = "/fragment@camera/__overlay__/is_sensor_gw2@5A:pinctrl-2:0";
		gpg1 = "/fragment@camera/__overlay__/is_sensor_gw2@5A/power_seq/scenario_normal_on/10:gpio:0\0/fragment@camera/__overlay__/is_sensor_gw2@5A/power_seq/scenario_normal_on/80:gpio:0\0/fragment@camera/__overlay__/is_sensor_gw2@5A/power_seq/scenario_normal_on/100:gpio:0\0/fragment@camera/__overlay__/is_sensor_gw2@5A/power_seq/scenario_normal_off/10:gpio:0\0/fragment@camera/__overlay__/is_sensor_gw2@5A/power_seq/scenario_vision_on/10:gpio:0\0/fragment@camera/__overlay__/is_sensor_gw2@5A/power_seq/scenario_vision_on/80:gpio:0\0/fragment@camera/__overlay__/is_sensor_gw2@5A/power_seq/scenario_vision_on/100:gpio:0\0/fragment@camera/__overlay__/is_sensor_gw2@5A/power_seq/scenario_vision_off/10:gpio:0";
		mipi_phy_csis0_m0s4s4s4_s22 = "/fragment@camera/__overlay__/is_sensor0@15030000:phys:0";
		dcphy_setfile_cphy = "/fragment@camera/__overlay__/is_sensor0@15030000:phy_setfile:0\0/fragment@camera/__overlay__/is_sensor2@15050000:phy_setfile:0";
		mipi_phy_csis2_m0s4s4s4_s22 = "/fragment@camera/__overlay__/is_sensor1@15040000:phys:0";
		dphy_setfile = "/fragment@camera/__overlay__/is_sensor1@15040000:phy_setfile:0";
		mipi_phy_csis1_m0s4s4s4_s22 = "/fragment@camera/__overlay__/is_sensor2@15050000:phys:0";
		mipi_phy_csis3_m0s4s4s4_s22 = "/fragment@camera/__overlay__/is_sensor3@15060000:phys:0";
		dphy_setfile_2lane = "/fragment@camera/__overlay__/is_sensor3@15060000:phy_setfile:0";
		pinctrl_1 = "/fragment@1:target:0";
		hsi2c_23 = "/fragment@2:target:0";
		gpm6 = "/fragment@2/__overlay__:gpios:0";
		gpm7 = "/fragment@2/__overlay__:gpios:12";
		hsi2c_29 = "/fragment@3:target:0";
		gpm19 = "/fragment@3/__overlay__:gpios:0";
		gpm20 = "/fragment@3/__overlay__:gpios:12";
		hsi2c_20 = "/fragment@4:target:0";
		gpm0 = "/fragment@4/__overlay__:gpios:0";
		gpm1 = "/fragment@4/__overlay__:gpios:12";
		hsi2c_25 = "/fragment@5:target:0";
		gpm10 = "/fragment@5/__overlay__:gpios:0";
		gpm11 = "/fragment@5/__overlay__:gpios:12";
		hsi2c_28 = "/fragment@6:target:0";
		gpm17 = "/fragment@6/__overlay__:gpios:0";
		gpm18 = "/fragment@6/__overlay__:gpios:12";
		hsi2c_21 = "/fragment@7:target:0";
		gpm2 = "/fragment@7/__overlay__:gpios:0";
		gpm3 = "/fragment@7/__overlay__:gpios:12";
		exynos_is = "/fragment@8:target:0";
		hsi2c_14 = "/fragment@9:target:0\0/fragment@12:target:0";
		pinctrl_3 = "/fragment@11:target:0\0/fragment@14:target:0\0/fragment@20:target:0";
		gpp2 = "/fragment@12/__overlay__/s5m3700x@14:s5m3700x-resetb:0\0/fragment@12/__overlay__/s5m3700x@14:s5m3700x-external-ldo-3-4v:0";
		gpc8 = "/fragment@12/__overlay__/s5m3700x@14:s5m3700x-external-ldo-1-8v:0";
		gpa0 = "/fragment@12/__overlay__/s5m3700x@14:s5m3700x-codec-int:0\0/fragment@29/__overlay__/sec-nfc@27:sec-nfc,irq-gpio:0\0/fragment@30/__overlay__/touchscreen@48:sec,irq_gpio:0\0/fragment@31/__overlay__/s2dos05_pmic@60:s2dos05,s2dos05_int:0\0/fragment@32/__overlay__/s2mf301@3A:s2mf301,irq-gpio:0\0/fragment@32/__overlay__/usbpd-s2mf301@3C:usbpd,usbpd_int:0";
		acpm_mfd_bus0 = "/fragment@15:target:0";
		acpm_mfd_bus1 = "/fragment@16:target:0";
		gpa1 = "/fragment@model/__overlay__/gpio_keys/button@3:gpios:0\0/fragment@29/__overlay__/sec-nfc@27:sec-nfc,clk_req-gpio:0";
		udc = "/fragment@model/__overlay__/usb_notifier:udc:0\0/fragment@24:target:0";
		gnss_rmem = "/fragment@model/__overlay__/gnssif:memory-region:0";
		abox_effect = "/fragment@model/__overlay__/sound:samsung,aux:0";
		abox_tplg = "/fragment@model/__overlay__/sound:samsung,aux:4";
		abox_rdma_0 = "/fragment@model/__overlay__/sound/rdma0/cpu:sound-dai:0\0/fragment@model/__overlay__/sound/rdma0/platform:sound-dai:0\0/fragment@model/__overlay__/sound/rdma0_be/cpu:sound-dai:0\0/fragment@model/__overlay__/sound/rdma0_be/platform:sound-dai:0";
		abox_rdma_1 = "/fragment@model/__overlay__/sound/rdma1/cpu:sound-dai:0\0/fragment@model/__overlay__/sound/rdma1/platform:sound-dai:0\0/fragment@model/__overlay__/sound/rdma1_be/cpu:sound-dai:0\0/fragment@model/__overlay__/sound/rdma1_be/platform:sound-dai:0";
		abox_rdma_2 = "/fragment@model/__overlay__/sound/rdma2/cpu:sound-dai:0\0/fragment@model/__overlay__/sound/rdma2/platform:sound-dai:0\0/fragment@model/__overlay__/sound/rdma2_be/cpu:sound-dai:0\0/fragment@model/__overlay__/sound/rdma2_be/platform:sound-dai:0";
		abox_rdma_3 = "/fragment@model/__overlay__/sound/rdma3/cpu:sound-dai:0\0/fragment@model/__overlay__/sound/rdma3/platform:sound-dai:0\0/fragment@model/__overlay__/sound/rdma3_be/cpu:sound-dai:0\0/fragment@model/__overlay__/sound/rdma3_be/platform:sound-dai:0";
		abox_rdma_4 = "/fragment@model/__overlay__/sound/rdma4/cpu:sound-dai:0\0/fragment@model/__overlay__/sound/rdma4/platform:sound-dai:0\0/fragment@model/__overlay__/sound/rdma4_be/cpu:sound-dai:0\0/fragment@model/__overlay__/sound/rdma4_be/platform:sound-dai:0";
		abox_rdma_5 = "/fragment@model/__overlay__/sound/rdma5/cpu:sound-dai:0\0/fragment@model/__overlay__/sound/rdma5/platform:sound-dai:0\0/fragment@model/__overlay__/sound/rdma5_be/cpu:sound-dai:0\0/fragment@model/__overlay__/sound/rdma5_be/platform:sound-dai:0";
		abox_rdma_6 = "/fragment@model/__overlay__/sound/rdma6/cpu:sound-dai:0\0/fragment@model/__overlay__/sound/rdma6/platform:sound-dai:0\0/fragment@model/__overlay__/sound/rdma6_be/cpu:sound-dai:0\0/fragment@model/__overlay__/sound/rdma6_be/platform:sound-dai:0";
		abox_rdma_7 = "/fragment@model/__overlay__/sound/rdma7/cpu:sound-dai:0\0/fragment@model/__overlay__/sound/rdma7/platform:sound-dai:0\0/fragment@model/__overlay__/sound/rdma7_be/cpu:sound-dai:0\0/fragment@model/__overlay__/sound/rdma7_be/platform:sound-dai:0";
		abox_rdma_8 = "/fragment@model/__overlay__/sound/rdma8/cpu:sound-dai:0\0/fragment@model/__overlay__/sound/rdma8/platform:sound-dai:0\0/fragment@model/__overlay__/sound/rdma8_be/cpu:sound-dai:0\0/fragment@model/__overlay__/sound/rdma8_be/platform:sound-dai:0";
		abox_rdma_9 = "/fragment@model/__overlay__/sound/rdma9/cpu:sound-dai:0\0/fragment@model/__overlay__/sound/rdma9/platform:sound-dai:0\0/fragment@model/__overlay__/sound/rdma9_be/cpu:sound-dai:0\0/fragment@model/__overlay__/sound/rdma9_be/platform:sound-dai:0";
		abox_rdma_10 = "/fragment@model/__overlay__/sound/rdma10/cpu:sound-dai:0\0/fragment@model/__overlay__/sound/rdma10/platform:sound-dai:0\0/fragment@model/__overlay__/sound/rdma10_be/cpu:sound-dai:0\0/fragment@model/__overlay__/sound/rdma10_be/platform:sound-dai:0";
		abox_rdma_11 = "/fragment@model/__overlay__/sound/rdma11/cpu:sound-dai:0\0/fragment@model/__overlay__/sound/rdma11/platform:sound-dai:0\0/fragment@model/__overlay__/sound/rdma11_be/cpu:sound-dai:0\0/fragment@model/__overlay__/sound/rdma11_be/platform:sound-dai:0";
		abox_wdma_0 = "/fragment@model/__overlay__/sound/wdma0/cpu:sound-dai:0\0/fragment@model/__overlay__/sound/wdma0/platform:sound-dai:0\0/fragment@model/__overlay__/sound/wdma0_be/cpu:sound-dai:0\0/fragment@model/__overlay__/sound/wdma0_be/platform:sound-dai:0";
		abox_wdma_1 = "/fragment@model/__overlay__/sound/wdma1/cpu:sound-dai:0\0/fragment@model/__overlay__/sound/wdma1/platform:sound-dai:0\0/fragment@model/__overlay__/sound/wdma1_be/cpu:sound-dai:0\0/fragment@model/__overlay__/sound/wdma1_be/platform:sound-dai:0";
		abox_wdma_2 = "/fragment@model/__overlay__/sound/wdma2/cpu:sound-dai:0\0/fragment@model/__overlay__/sound/wdma2/platform:sound-dai:0\0/fragment@model/__overlay__/sound/wdma2_be/cpu:sound-dai:0\0/fragment@model/__overlay__/sound/wdma2_be/platform:sound-dai:0";
		abox_wdma_3 = "/fragment@model/__overlay__/sound/wdma3/cpu:sound-dai:0\0/fragment@model/__overlay__/sound/wdma3/platform:sound-dai:0\0/fragment@model/__overlay__/sound/wdma3_be/cpu:sound-dai:0\0/fragment@model/__overlay__/sound/wdma3_be/platform:sound-dai:0";
		abox_wdma_4 = "/fragment@model/__overlay__/sound/wdma4/cpu:sound-dai:0\0/fragment@model/__overlay__/sound/wdma4/platform:sound-dai:0\0/fragment@model/__overlay__/sound/wdma4_be/cpu:sound-dai:0\0/fragment@model/__overlay__/sound/wdma4_be/platform:sound-dai:0";
		abox_wdma_5 = "/fragment@model/__overlay__/sound/wdma5/cpu:sound-dai:0\0/fragment@model/__overlay__/sound/wdma5/platform:sound-dai:0\0/fragment@model/__overlay__/sound/wdma5_be/cpu:sound-dai:0\0/fragment@model/__overlay__/sound/wdma5_be/platform:sound-dai:0";
		abox_wdma_6 = "/fragment@model/__overlay__/sound/wdma6/cpu:sound-dai:0\0/fragment@model/__overlay__/sound/wdma6/platform:sound-dai:0\0/fragment@model/__overlay__/sound/wdma6_be/cpu:sound-dai:0\0/fragment@model/__overlay__/sound/wdma6_be/platform:sound-dai:0";
		abox_wdma_7 = "/fragment@model/__overlay__/sound/wdma7/cpu:sound-dai:0\0/fragment@model/__overlay__/sound/wdma7/platform:sound-dai:0\0/fragment@model/__overlay__/sound/wdma7_be/cpu:sound-dai:0\0/fragment@model/__overlay__/sound/wdma7_be/platform:sound-dai:0";
		abox_wdma_8 = "/fragment@model/__overlay__/sound/wdma8/cpu:sound-dai:0\0/fragment@model/__overlay__/sound/wdma8/platform:sound-dai:0\0/fragment@model/__overlay__/sound/wdma8_be/cpu:sound-dai:0\0/fragment@model/__overlay__/sound/wdma8_be/platform:sound-dai:0";
		abox_wdma_9 = "/fragment@model/__overlay__/sound/wdma9/cpu:sound-dai:0\0/fragment@model/__overlay__/sound/wdma9/platform:sound-dai:0\0/fragment@model/__overlay__/sound/wdma9_be/cpu:sound-dai:0\0/fragment@model/__overlay__/sound/wdma9_be/platform:sound-dai:0";
		abox_wdma_10 = "/fragment@model/__overlay__/sound/wdma10/cpu:sound-dai:0\0/fragment@model/__overlay__/sound/wdma10/platform:sound-dai:0\0/fragment@model/__overlay__/sound/wdma10_be/cpu:sound-dai:0\0/fragment@model/__overlay__/sound/wdma10_be/platform:sound-dai:0";
		abox_wdma_11 = "/fragment@model/__overlay__/sound/wdma11/cpu:sound-dai:0\0/fragment@model/__overlay__/sound/wdma11/platform:sound-dai:0\0/fragment@model/__overlay__/sound/wdma11_be/cpu:sound-dai:0\0/fragment@model/__overlay__/sound/wdma11_be/platform:sound-dai:0";
		abox_dual_0 = "/fragment@model/__overlay__/sound/dual0/cpu:sound-dai:0\0/fragment@model/__overlay__/sound/dual0/platform:sound-dai:0";
		abox_dual_1 = "/fragment@model/__overlay__/sound/dual1/cpu:sound-dai:0\0/fragment@model/__overlay__/sound/dual1/platform:sound-dai:0";
		abox_dual_2 = "/fragment@model/__overlay__/sound/dual2/cpu:sound-dai:0\0/fragment@model/__overlay__/sound/dual2/platform:sound-dai:0";
		abox_dual_3 = "/fragment@model/__overlay__/sound/dual3/cpu:sound-dai:0\0/fragment@model/__overlay__/sound/dual3/platform:sound-dai:0";
		abox_dual_4 = "/fragment@model/__overlay__/sound/dual4/cpu:sound-dai:0\0/fragment@model/__overlay__/sound/dual4/platform:sound-dai:0";
		abox_dual_5 = "/fragment@model/__overlay__/sound/dual5/cpu:sound-dai:0\0/fragment@model/__overlay__/sound/dual5/platform:sound-dai:0";
		abox_dual_6 = "/fragment@model/__overlay__/sound/dual6/cpu:sound-dai:0\0/fragment@model/__overlay__/sound/dual6/platform:sound-dai:0";
		abox_dual_7 = "/fragment@model/__overlay__/sound/dual7/cpu:sound-dai:0\0/fragment@model/__overlay__/sound/dual7/platform:sound-dai:0";
		abox_dual_8 = "/fragment@model/__overlay__/sound/dual8/cpu:sound-dai:0\0/fragment@model/__overlay__/sound/dual8/platform:sound-dai:0";
		abox_dual_9 = "/fragment@model/__overlay__/sound/dual9/cpu:sound-dai:0\0/fragment@model/__overlay__/sound/dual9/platform:sound-dai:0";
		abox_dual_10 = "/fragment@model/__overlay__/sound/dual10/cpu:sound-dai:0\0/fragment@model/__overlay__/sound/dual10/platform:sound-dai:0";
		abox_dual_11 = "/fragment@model/__overlay__/sound/dual11/cpu:sound-dai:0\0/fragment@model/__overlay__/sound/dual11/platform:sound-dai:0";
		abox_ddma_0 = "/fragment@model/__overlay__/sound/ddma0/cpu:sound-dai:0\0/fragment@model/__overlay__/sound/ddma0/platform:sound-dai:0";
		abox_ddma_1 = "/fragment@model/__overlay__/sound/ddma1/cpu:sound-dai:0\0/fragment@model/__overlay__/sound/ddma1/platform:sound-dai:0";
		abox_ddma_2 = "/fragment@model/__overlay__/sound/ddma2/cpu:sound-dai:0\0/fragment@model/__overlay__/sound/ddma2/platform:sound-dai:0";
		abox_ddma_3 = "/fragment@model/__overlay__/sound/ddma3/cpu:sound-dai:0\0/fragment@model/__overlay__/sound/ddma3/platform:sound-dai:0";
		abox_ddma_4 = "/fragment@model/__overlay__/sound/ddma4/cpu:sound-dai:0\0/fragment@model/__overlay__/sound/ddma4/platform:sound-dai:0";
		abox_ddma_5 = "/fragment@model/__overlay__/sound/ddma5/cpu:sound-dai:0\0/fragment@model/__overlay__/sound/ddma5/platform:sound-dai:0";
		abox_uaif_0 = "/fragment@model/__overlay__/sound/uaif0/cpu:sound-dai:0";
		abox_uaif_1 = "/fragment@model/__overlay__/sound/uaif1/cpu:sound-dai:0";
		abox_uaif_2 = "/fragment@model/__overlay__/sound/uaif2/cpu:sound-dai:0\0/fragment@18:target:0";
		abox_uaif_3 = "/fragment@model/__overlay__/sound/uaif3/cpu:sound-dai:0\0/fragment@19:target:0";
		abox_uaif_4 = "/fragment@model/__overlay__/sound/uaif4/cpu:sound-dai:0";
		abox_uaif_5 = "/fragment@model/__overlay__/sound/uaif5/cpu:sound-dai:0";
		abox_uaif_6 = "/fragment@model/__overlay__/sound/uaif6/cpu:sound-dai:0";
		abox_dsif = "/fragment@model/__overlay__/sound/dsif0/cpu:sound-dai:0";
		abox_spdy = "/fragment@model/__overlay__/sound/spdy/cpu:sound-dai:0";
		abox_udma_rd_0 = "/fragment@model/__overlay__/sound/udma_rd0/cpu:sound-dai:0";
		abox_udma_wr_0 = "/fragment@model/__overlay__/sound/udma_wr0/cpu:sound-dai:0";
		abox_udma_wr_dual_0 = "/fragment@model/__overlay__/sound/udma_wr_dual0/cpu:sound-dai:0";
		abox_udma_wr_debug_0 = "/fragment@model/__overlay__/sound/udma_wr_dbg0/cpu:sound-dai:0";
		abox = "/fragment@model/__overlay__/sound/usb/cpu:sound-dai:0\0/fragment@model/__overlay__/sound/fwd/cpu:sound-dai:0\0/fragment@26/__overlay__:abox:0";
		chosen = "/fragment@17:target:0";
		hsi2c_7 = "/fragment@22:target:0";
		gpc14 = "/fragment@22/__overlay__/cs35l41@40:interrupt-parent:0";
		gpc9 = "/fragment@22/__overlay__/cs35l41@40:reset-gpios:0";
		gpp3 = "/fragment@22/__overlay__/cs35l41@41:interrupt-parent:0\0/fragment@22/__overlay__/cs35l41@41:reset-gpios:0";
		serial_0 = "/fragment@23:target:0";
		ufs = "/fragment@25:target:0";
		usbdrd_dwc3 = "/fragment@26:target:0";
		abox_gic = "/fragment@26/__overlay__:samsung,abox-gic:0";
		usbdrd_phy0 = "/fragment@27:target:0";
		hsi2c_4 = "/fragment@29:target:0";
		gpc4 = "/fragment@29/__overlay__/sec-nfc@27:sec-nfc,ven-gpio:0";
		gpc5 = "/fragment@29/__overlay__/sec-nfc@27:sec-nfc,firm-gpio:0";
		gpc10 = "/fragment@29/__overlay__/sec-nfc@27:sec-nfc,ldo_en:0";
		hsi2c_6 = "/fragment@30:target:0";
		hsi2c_8 = "/fragment@31:target:0";
		hsi2c_9 = "/fragment@32:target:0";
		gpc3 = "/fragment@32/__overlay__/s2mc501-direct-charger@33:s2mc501,irq-gpio:0";
		gpc2 = "/fragment@32/__overlay__/s2mc501-direct-charger@33:s2mc501,enable-gpio:0";
		hsi2c_10 = "/fragment@33:target:0";
		drmdsim_0 = "/fragment@34:target:0\0/fragment@36:target:0\0/fragment@37:target:0\0/fragment@38:target:0\0/fragment@39:target:0";
		gpc7 = "/fragment@34/__overlay__/drmpanel:reset-gpios:0";
		fm = "/fragment@35:target:0";
		gpg2 = "/fragment@35/__overlay__:elna_gpio:0";
	};

	__local_fixups__ {

		fragment@modemif {

			__overlay__ {

				cpif {
					pinctrl-0 = <0x00>;
				};
			};
		};

		fragment@camera {

			__overlay__ {

				is-flash-s2mf301@0 {
					sensor-module = <0x00>;
				};

				is-flash-s2mf301_2@0 {
					sensor-module = <0x00>;
				};
			};
		};

		fragment@2 {

			__overlay__ {
				pinctrl-0 = <0x00>;
				pinctrl-1 = <0x00>;
				pinctrl-2 = <0x00>;

				is-2la@2D {
					sensor-module = <0x00>;
				};
			};
		};

		fragment@3 {

			__overlay__ {
				pinctrl-0 = <0x00>;
				pinctrl-1 = <0x00>;
				pinctrl-2 = <0x00>;

				is-gw2@5A {
					sensor-module = <0x00>;
				};
			};
		};

		fragment@4 {

			__overlay__ {
				pinctrl-0 = <0x00>;
				pinctrl-1 = <0x00>;
				pinctrl-2 = <0x00>;

				is-3h1@35 {
					sensor-module = <0x00>;
				};
			};
		};

		fragment@5 {

			__overlay__ {
				pinctrl-0 = <0x00>;
				pinctrl-1 = <0x00>;
				pinctrl-2 = <0x00>;
			};
		};

		fragment@6 {

			__overlay__ {
				pinctrl-0 = <0x00>;
				pinctrl-1 = <0x00>;
				pinctrl-2 = <0x00>;

				is-actuator@0C {
					sensor-module = <0x00>;
				};
			};
		};

		fragment@7 {

			__overlay__ {
				pinctrl-0 = <0x00>;
				pinctrl-1 = <0x00>;
				pinctrl-2 = <0x00>;

				is-actuator@0C {
					sensor-module = <0x00>;
				};
			};
		};

		fragment@12 {

			__overlay__ {

				s5m3700x@14 {
					pinctrl-0 = <0x00 0x04 0x08 0x0c>;
					mic-adc-range = <0x00>;
					jack-imp-range = <0x00>;
					wtp-ldet-range = <0x00>;
					but-zones-list = <0x00 0x0c 0x18 0x24>;
				};
			};
		};

		fragment@15 {

			__overlay__ {

				s2mpu15mfd@1f {
					pinctrl-0 = <0x00 0x04>;
				};
			};
		};

		fragment@model {

			__overlay__ {

				gpio_keys {
					pinctrl-0 = <0x00 0x04>;
				};

				gnssif {
					mbox_info = <0x00>;
				};

				sound {
					samsung,codec = <0x00 0x04>;

					uaif0 {

						codec {
							sound-dai = <0x00>;
						};
					};

					uaif1 {

						codec {
							sound-dai = <0x00 0x08>;
						};
					};
				};
			};
		};

		fragment@22 {

			__overlay__ {

				cs35l41@40 {
					pinctrl-0 = <0x00 0x04>;
					VA-supply = <0x00>;
					VP-supply = <0x00>;
				};

				cs35l41@41 {
					pinctrl-0 = <0x00 0x04>;
					VA-supply = <0x00>;
					VP-supply = <0x00>;
				};
			};
		};

		fragment@25 {

			__overlay__ {
				vcc-supply = <0x00>;
				vccq-supply = <0x00>;
			};
		};

		fragment@26 {

			__overlay__ {
				vdd33_usb-supply = <0x00>;
			};
		};

		fragment@27 {

			__overlay__ {
				hs_tune_param = <0x00>;
				vdd33_usb-supply = <0x00>;
			};
		};

		fragment@29 {

			__overlay__ {

				sec-nfc@27 {
					pinctrl-0 = <0x00 0x04 0x08 0x0c>;
				};
			};
		};

		fragment@30 {

			__overlay__ {

				touchscreen@48 {
					pinctrl-0 = <0x00>;
					pinctrl-1 = <0x00>;
					dvdd-supply = <0x00>;
					avdd-supply = <0x00>;
				};
			};
		};

		fragment@31 {

			__overlay__ {

				s2dos05_pmic@60 {
					pinctrl-0 = <0x00>;
				};
			};
		};

		fragment@32 {

			__overlay__ {

				s2mf301@3A {
					pinctrl-0 = <0x00>;
				};

				usbpd-s2mf301@3C {
					pinctrl-0 = <0x00>;
				};

				s2mc501-direct-charger@33 {
					pinctrl-0 = <0x00>;
				};
			};
		};

		fragment@33 {

			__overlay__ {

				s2mpb06_pmic@55 {
					pinctrl-0 = <0x00>;
				};
			};
		};

		fragment@34 {

			__overlay__ {

				drmpanel {
					vddi-supply = <0x00>;
					vci-supply = <0x00>;
					vddr-supply = <0x00>;
				};
			};
		};
	};
};
